AUTOSAR XML (schema 4-2-2)
package /STELLANTIS/EPT/ASWCs
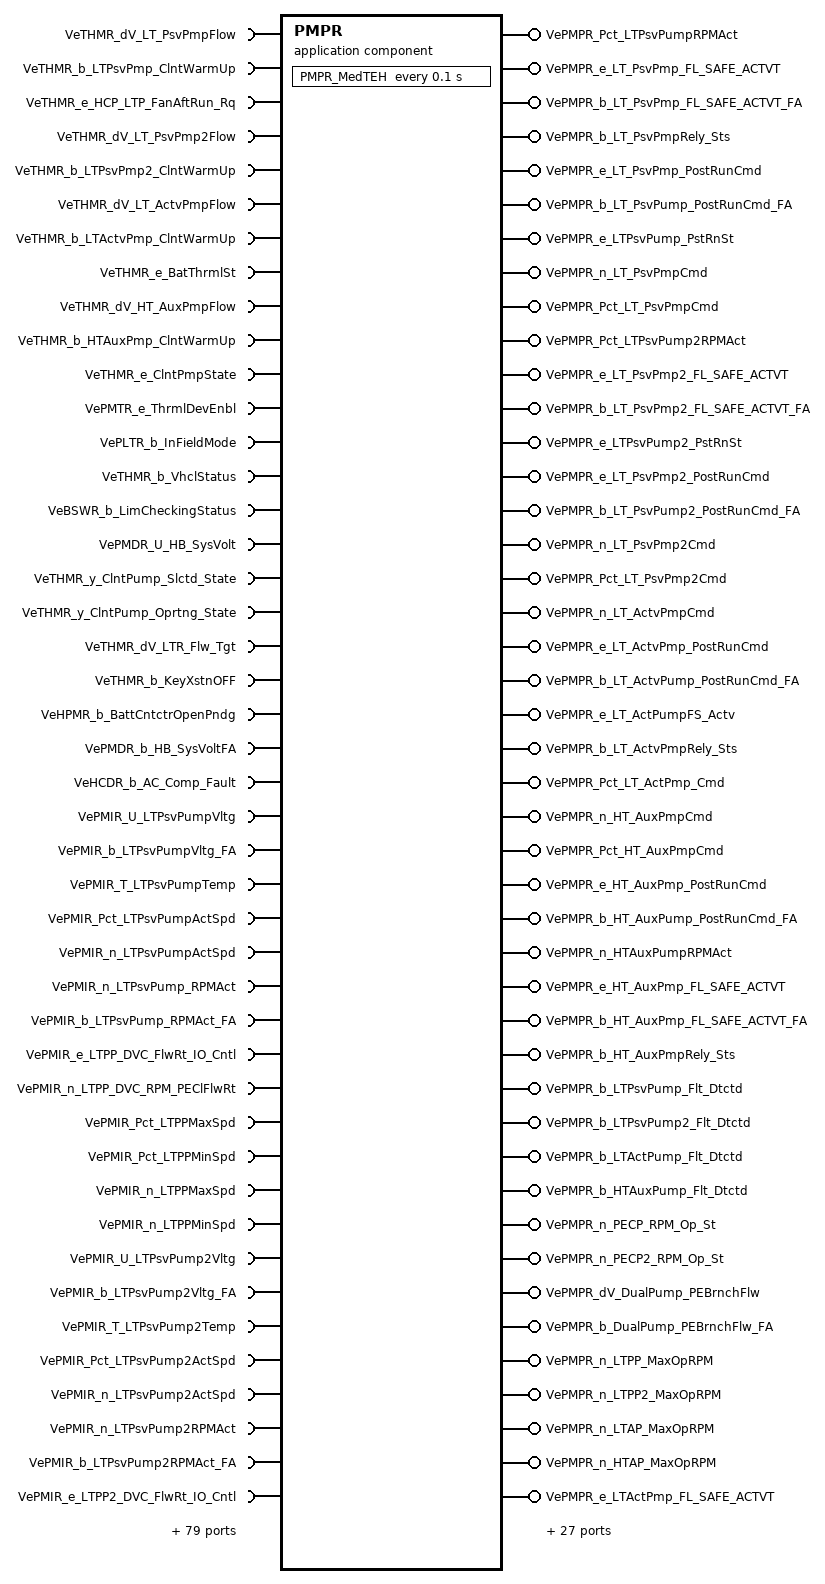
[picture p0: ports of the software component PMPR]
  application sw component type PMPR
    119 x require port:
      VeTHMR_dV_LT_PsvPmpFlow: variation-point={short-label=vpVeTHMR_dV_LT_PsvPmpFlow, sw-syscond=1}, nonqueued-receiver-com-spec{data-element=Value, init-value=0}, required-interface=VeTHMR_dV_LT_PsvPmpFlow
      VeTHMR_b_LTPsvPmp_ClntWarmUp: variation-point={short-label=vpVeTHMR_b_LTPsvPmp_ClntWarmUp, sw-syscond=1}, nonqueued-receiver-com-spec{data-element=Value, init-value=0}, required-interface=VeTHMR_b_LTPsvPmp_ClntWarmUp
      VeTHMR_e_HCP_LTP_FanAftRun_Rq: variation-point={short-label=vpVeTHMR_e_HCP_LTP_FanAftRun_Rq, sw-syscond=1}, nonqueued-receiver-com-spec{data-element=Value, init-value=CeTMIR_e_No_AftRunRequest}, required-interface=VeTHMR_e_HCP_LTP_FanAftRun_Rq
      VeTHMR_dV_LT_PsvPmp2Flow: variation-point={short-label=vpVeTHMR_dV_LT_PsvPmp2Flow, sw-syscond=1}, nonqueued-receiver-com-spec{data-element=Value, init-value=0}, required-interface=VeTHMR_dV_LT_PsvPmp2Flow
      VeTHMR_b_LTPsvPmp2_ClntWarmUp: variation-point={short-label=vpVeTHMR_b_LTPsvPmp2_ClntWarmUp, sw-syscond=1}, nonqueued-receiver-com-spec{data-element=Value, init-value=0}, required-interface=VeTHMR_b_LTPsvPmp2_ClntWarmUp
      VeTHMR_dV_LT_ActvPmpFlow: variation-point={short-label=vpVeTHMR_dV_LT_ActvPmpFlow, sw-syscond=1}, nonqueued-receiver-com-spec{data-element=Value, init-value=0}, required-interface=VeTHMR_dV_LT_ActvPmpFlow
      VeTHMR_b_LTActvPmp_ClntWarmUp: variation-point={short-label=vpVeTHMR_b_LTActvPmp_ClntWarmUp, sw-syscond=1}, nonqueued-receiver-com-spec{data-element=Value, init-value=0}, required-interface=VeTHMR_b_LTActvPmp_ClntWarmUp
      VeTHMR_e_BatThrmlSt: variation-point={short-label=vpVeTHMR_e_BatThrmlSt, sw-syscond=1}, nonqueued-receiver-com-spec{data-element=Value, init-value=CeTHMR_e_NoConditioning}, required-interface=VeTHMR_e_BatThrmlSt
      VeTHMR_dV_HT_AuxPmpFlow: variation-point={short-label=vpVeTHMR_dV_HT_AuxPmpFlow, sw-syscond=1}, nonqueued-receiver-com-spec{data-element=Value, init-value=0}, required-interface=VeTHMR_dV_HT_AuxPmpFlow
      VeTHMR_b_HTAuxPmp_ClntWarmUp: variation-point={short-label=vpVeTHMR_b_HTAuxPmp_ClntWarmUp, sw-syscond=1}, nonqueued-receiver-com-spec{data-element=Value, init-value=0}, required-interface=VeTHMR_b_HTAuxPmp_ClntWarmUp
      VeTHMR_e_ClntPmpState: variation-point={short-label=vpVeTHMR_e_ClntPmpState, sw-syscond=1}, nonqueued-receiver-com-spec{data-element=Value, init-value=CeTHMR_e_NoPump_On}, required-interface=VeTHMR_e_ClntPmpState
      VePMTR_e_ThrmlDevEnbl: variation-point={short-label=vpVePMTR_e_ThrmlDevEnbl, sw-syscond=1}, nonqueued-receiver-com-spec{data-element=Value, init-value=CePMTR_e_DISBL_All_Thrml}, required-interface=VePMTR_e_ThrmlDevEnbl
      VePLTR_b_InFieldMode: variation-point={short-label=vpVePLTR_b_InFieldMode, sw-syscond=1}, nonqueued-receiver-com-spec{data-element=Value, init-value=0}, required-interface=VePLTR_b_InFieldMode
      VeTHMR_b_VhclStatus: variation-point={short-label=vpVeTHMR_b_VhclStatus, sw-syscond=1}, nonqueued-receiver-com-spec{data-element=Value, init-value=0}, required-interface=VeTHMR_b_VhclStatus
      VeBSWR_b_LimCheckingStatus: variation-point={short-label=vpVeBSWR_b_LimCheckingStatus, sw-syscond=1}, nonqueued-receiver-com-spec{data-element=Value, init-value=0}, required-interface=VeBSWR_b_LimCheckingStatus
      VePMDR_U_HB_SysVolt: variation-point={short-label=vpVePMDR_U_HB_SysVolt, sw-syscond=1}, nonqueued-receiver-com-spec{data-element=Value, init-value=0}, required-interface=VePMDR_U_HB_SysVolt
      VeTHMR_y_ClntPump_Slctd_State: variation-point={short-label=vpVeTHMR_y_ClntPump_Slctd_State, sw-syscond=1}, nonqueued-receiver-com-spec{data-element=Value, init-value=0}, required-interface=VeTHMR_y_ClntPump_Slctd_State
      VeTHMR_y_ClntPump_Oprtng_State: variation-point={short-label=vpVeTHMR_y_ClntPump_Oprtng_State, sw-syscond=1}, nonqueued-receiver-com-spec{data-element=Value, init-value=0}, required-interface=VeTHMR_y_ClntPump_Oprtng_State
      VeTHMR_dV_LTR_Flw_Tgt: variation-point={short-label=vpVeTHMR_dV_LTR_Flw_Tgt, sw-syscond=1}, nonqueued-receiver-com-spec{data-element=Value, init-value=0}, required-interface=VeTHMR_dV_LTR_Flw_Tgt
      VeTHMR_b_KeyXstnOFF: variation-point={short-label=vpVeTHMR_b_KeyXstnOFF, sw-syscond=1}, nonqueued-receiver-com-spec{data-element=Value, init-value=0}, required-interface=VeTHMR_b_KeyXstnOFF
      VeHPMR_b_BattCntctrOpenPndg: variation-point={short-label=vpVeHPMR_b_BattCntctrOpenPndg, sw-syscond=1}, nonqueued-receiver-com-spec{data-element=Value, init-value=0}, required-interface=VeHPMR_b_BattCntctrOpenPndg
      VePMDR_b_HB_SysVoltFA: variation-point={short-label=vpVePMDR_b_HB_SysVoltFA, sw-syscond=1}, nonqueued-receiver-com-spec{data-element=Value, init-value=0}, required-interface=VePMDR_b_HB_SysVoltFA
      VeHCDR_b_AC_Comp_Fault: variation-point={short-label=vpVeHCDR_b_AC_Comp_Fault, sw-syscond=1}, nonqueued-receiver-com-spec{data-element=Value, init-value=0}, required-interface=VeHCDR_b_AC_Comp_Fault
      VePMIR_U_LTPsvPumpVltg: variation-point={short-label=vpVePMIR_U_LTPsvPumpVltg, sw-syscond=1}, nonqueued-receiver-com-spec{data-element=Value, init-value=0}, required-interface=VePMIR_U_LTPsvPumpVltg
      VePMIR_b_LTPsvPumpVltg_FA: variation-point={short-label=vpVePMIR_b_LTPsvPumpVltg_FA, sw-syscond=1}, nonqueued-receiver-com-spec{data-element=Value, init-value=0}, required-interface=VePMIR_b_LTPsvPumpVltg_FA
      VePMIR_T_LTPsvPumpTemp: variation-point={short-label=vpVePMIR_T_LTPsvPumpTemp, sw-syscond=1}, nonqueued-receiver-com-spec{data-element=Value, init-value=0}, required-interface=VePMIR_T_LTPsvPumpTemp
      VePMIR_Pct_LTPsvPumpActSpd: variation-point={short-label=vpVePMIR_Pct_LTPsvPumpActSpd, sw-syscond=1}, nonqueued-receiver-com-spec{data-element=Value, init-value=0}, required-interface=VePMIR_Pct_LTPsvPumpActSpd
      VePMIR_n_LTPsvPumpActSpd: variation-point={short-label=vpVePMIR_n_LTPsvPumpActSpd, sw-syscond=1}, nonqueued-receiver-com-spec{data-element=Value, init-value=0}, required-interface=VePMIR_n_LTPsvPumpActSpd
      VePMIR_n_LTPsvPump_RPMAct: variation-point={short-label=vpVePMIR_n_LTPsvPump_RPMAct, sw-syscond=1}, nonqueued-receiver-com-spec{data-element=Value, init-value=0}, required-interface=VePMIR_n_LTPsvPump_RPMAct
      VePMIR_b_LTPsvPump_RPMAct_FA: variation-point={short-label=vpVePMIR_b_LTPsvPump_RPMAct_FA, sw-syscond=1}, nonqueued-receiver-com-spec{data-element=Value, init-value=0}, required-interface=VePMIR_b_LTPsvPump_RPMAct_FA
      VePMIR_e_LTPP_DVC_FlwRt_IO_Cntl: variation-point={short-label=vpVePMIR_e_LTPP_DVC_FlwRt_IO_Cntl, sw-syscond=1}, nonqueued-receiver-com-spec{data-element=Value, init-value=CeTAIR_e_Return_Control_to_ECU}, required-interface=VePMIR_e_LTPP_DVC_FlwRt_IO_Cntl
      VePMIR_n_LTPP_DVC_RPM_PEClFlwRt: variation-point={short-label=vpVePMIR_n_LTPP_DVC_RPM_PEClFlwRt, sw-syscond=1}, nonqueued-receiver-com-spec{data-element=Value, init-value=0}, required-interface=VePMIR_n_LTPP_DVC_RPM_PEClFlwRt
      VePMIR_Pct_LTPPMaxSpd: variation-point={short-label=vpVePMIR_Pct_LTPPMaxSpd, sw-syscond=1}, nonqueued-receiver-com-spec{data-element=Value, init-value=0}, required-interface=VePMIR_Pct_LTPPMaxSpd
      VePMIR_Pct_LTPPMinSpd: variation-point={short-label=vpVePMIR_Pct_LTPPMinSpd, sw-syscond=1}, nonqueued-receiver-com-spec{data-element=Value, init-value=0}, required-interface=VePMIR_Pct_LTPPMinSpd
      VePMIR_n_LTPPMaxSpd: variation-point={short-label=vpVePMIR_n_LTPPMaxSpd, sw-syscond=1}, nonqueued-receiver-com-spec{data-element=Value, init-value=0}, required-interface=VePMIR_n_LTPPMaxSpd
      VePMIR_n_LTPPMinSpd: variation-point={short-label=vpVePMIR_n_LTPPMinSpd, sw-syscond=1}, nonqueued-receiver-com-spec{data-element=Value, init-value=0}, required-interface=VePMIR_n_LTPPMinSpd
      VePMIR_U_LTPsvPump2Vltg: variation-point={short-label=vpVePMIR_U_LTPsvPump2Vltg, sw-syscond=1}, nonqueued-receiver-com-spec{data-element=Value, init-value=0}, required-interface=VePMIR_U_LTPsvPump2Vltg
      VePMIR_b_LTPsvPump2Vltg_FA: variation-point={short-label=vpVePMIR_b_LTPsvPump2Vltg_FA, sw-syscond=1}, nonqueued-receiver-com-spec{data-element=Value, init-value=0}, required-interface=VePMIR_b_LTPsvPump2Vltg_FA
      VePMIR_T_LTPsvPump2Temp: variation-point={short-label=vpVePMIR_T_LTPsvPump2Temp, sw-syscond=1}, nonqueued-receiver-com-spec{data-element=Value, init-value=0}, required-interface=VePMIR_T_LTPsvPump2Temp
      VePMIR_Pct_LTPsvPump2ActSpd: variation-point={short-label=vpVePMIR_Pct_LTPsvPump2ActSpd, sw-syscond=1}, nonqueued-receiver-com-spec{data-element=Value, init-value=0}, required-interface=VePMIR_Pct_LTPsvPump2ActSpd
      VePMIR_n_LTPsvPump2ActSpd: variation-point={short-label=vpVePMIR_n_LTPsvPump2ActSpd, sw-syscond=1}, nonqueued-receiver-com-spec{data-element=Value, init-value=0}, required-interface=VePMIR_n_LTPsvPump2ActSpd
      VePMIR_n_LTPsvPump2RPMAct: variation-point={short-label=vpVePMIR_n_LTPsvPump2RPMAct, sw-syscond=1}, nonqueued-receiver-com-spec{data-element=Value, init-value=0}, required-interface=VePMIR_n_LTPsvPump2RPMAct
      VePMIR_b_LTPsvPump2RPMAct_FA: variation-point={short-label=vpVePMIR_b_LTPsvPump2RPMAct_FA, sw-syscond=1}, nonqueued-receiver-com-spec{data-element=Value, init-value=0}, required-interface=VePMIR_b_LTPsvPump2RPMAct_FA
      VePMIR_e_LTPP2_DVC_FlwRt_IO_Cntl: variation-point={short-label=vpVePMIR_e_LTPP2_DVC_FlwRt_IO_Cntl, sw-syscond=1}, nonqueued-receiver-com-spec{data-element=Value, init-value=CeTAIR_e_Return_Control_to_ECU}, required-interface=VePMIR_e_LTPP2_DVC_FlwRt_IO_Cntl
      VePMIR_n_LTPP2_DVC_RPM_PEClFlwRt: variation-point={short-label=vpVePMIR_n_LTPP2_DVC_RPM_PEClFlwRt, sw-syscond=1}, nonqueued-receiver-com-spec{data-element=Value, init-value=0}, required-interface=VePMIR_n_LTPP2_DVC_RPM_PEClFlwRt
      VePMIR_Pct_LTPP2MaxSpd: variation-point={short-label=vpVePMIR_Pct_LTPP2MaxSpd, sw-syscond=1}, nonqueued-receiver-com-spec{data-element=Value, init-value=0}, required-interface=VePMIR_Pct_LTPP2MaxSpd
      VePMIR_Pct_LTPP2MinSpd: variation-point={short-label=vpVePMIR_Pct_LTPP2MinSpd, sw-syscond=1}, nonqueued-receiver-com-spec{data-element=Value, init-value=0}, required-interface=VePMIR_Pct_LTPP2MinSpd
      VePMIR_n_LTPP2MaxSpd: variation-point={short-label=vpVePMIR_n_LTPP2MaxSpd, sw-syscond=1}, nonqueued-receiver-com-spec{data-element=Value, init-value=0}, required-interface=VePMIR_n_LTPP2MaxSpd
      VePMIR_n_LTPP2MinSpd: variation-point={short-label=vpVePMIR_n_LTPP2MinSpd, sw-syscond=1}, nonqueued-receiver-com-spec{data-element=Value, init-value=0}, required-interface=VePMIR_n_LTPP2MinSpd
      VePMIR_U_LTActvPumpVlt: variation-point={short-label=vpVePMIR_U_LTActvPumpVlt, sw-syscond=1}, nonqueued-receiver-com-spec{data-element=Value, init-value=0}, required-interface=VePMIR_U_LTActvPumpVlt
      VePMIR_b_LTActvPumpVlt_FA: variation-point={short-label=vpVePMIR_b_LTActvPumpVlt_FA, sw-syscond=1}, nonqueued-receiver-com-spec{data-element=Value, init-value=0}, required-interface=VePMIR_b_LTActvPumpVlt_FA
      VePMIR_T_LTActvPumpTemp: variation-point={short-label=vpVePMIR_T_LTActvPumpTemp, sw-syscond=1}, nonqueued-receiver-com-spec{data-element=Value, init-value=0}, required-interface=VePMIR_T_LTActvPumpTemp
      VePMIR_n_LTActvPumpRPMAct: variation-point={short-label=vpVePMIR_n_LTActvPumpRPMAct, sw-syscond=1}, nonqueued-receiver-com-spec{data-element=Value, init-value=0}, required-interface=VePMIR_n_LTActvPumpRPMAct
      VePMIR_b_LTActvPumpRPMAct_FA: variation-point={short-label=vpVePMIR_b_LTActvPumpRPMAct_FA, sw-syscond=1}, nonqueued-receiver-com-spec{data-element=Value, init-value=0}, required-interface=VePMIR_b_LTActvPumpRPMAct_FA
      VePMIR_e_LTAP_DVC_FlwRt_IO_Cntl: variation-point={short-label=vpVePMIR_e_LTAP_DVC_FlwRt_IO_Cntl, sw-syscond=1}, nonqueued-receiver-com-spec{data-element=Value, init-value=CeTAIR_e_Return_Control_to_ECU}, required-interface=VePMIR_e_LTAP_DVC_FlwRt_IO_Cntl
      VePMIR_n_LTAP_DVC_RPM_PEClFlwRt: variation-point={short-label=vpVePMIR_n_LTAP_DVC_RPM_PEClFlwRt, sw-syscond=1}, nonqueued-receiver-com-spec{data-element=Value, init-value=0}, required-interface=VePMIR_n_LTAP_DVC_RPM_PEClFlwRt
      VePMIR_U_HTAuxPumpVltg: variation-point={short-label=vpVePMIR_U_HTAuxPumpVltg, sw-syscond=1}, nonqueued-receiver-com-spec{data-element=Value, init-value=0}, required-interface=VePMIR_U_HTAuxPumpVltg
      VePMIR_b_HTAuxPumpVltg_FA: variation-point={short-label=vpVePMIR_b_HTAuxPumpVltg_FA, sw-syscond=1}, nonqueued-receiver-com-spec{data-element=Value, init-value=0}, required-interface=VePMIR_b_HTAuxPumpVltg_FA
      VePMIR_T_HTAuxPumpTemp: variation-point={short-label=vpVePMIR_T_HTAuxPumpTemp, sw-syscond=1}, nonqueued-receiver-com-spec{data-element=Value, init-value=0}, required-interface=VePMIR_T_HTAuxPumpTemp
      VePMIR_Pct_HTAuxPumpActSpd: variation-point={short-label=vpVePMIR_Pct_HTAuxPumpActSpd, sw-syscond=1}, nonqueued-receiver-com-spec{data-element=Value, init-value=0}, required-interface=VePMIR_Pct_HTAuxPumpActSpd
      VePMIR_n_HTAuxPumpRPMAct: variation-point={short-label=vpVePMIR_n_HTAuxPumpRPMAct, sw-syscond=1}, nonqueued-receiver-com-spec{data-element=Value, init-value=0}, required-interface=VePMIR_n_HTAuxPumpRPMAct
      VePMIR_e_HTAP_DVC_FlwRt_IO_Cntl: variation-point={short-label=vpVePMIR_e_HTAP_DVC_FlwRt_IO_Cntl, sw-syscond=1}, nonqueued-receiver-com-spec{data-element=Value, init-value=CeTAIR_e_Return_Control_to_ECU}, required-interface=VePMIR_e_HTAP_DVC_FlwRt_IO_Cntl
      VePMIR_n_HTAP_DVC_RPM_PEClFlwRt: variation-point={short-label=vpVePMIR_n_HTAP_DVC_RPM_PEClFlwRt, sw-syscond=1}, nonqueued-receiver-com-spec{data-element=Value, init-value=0}, required-interface=VePMIR_n_HTAP_DVC_RPM_PEClFlwRt
      VePMIR_Pct_HTAPMaxSpd: variation-point={short-label=vpVePMIR_Pct_HTAPMaxSpd, sw-syscond=1}, nonqueued-receiver-com-spec{data-element=Value, init-value=0}, required-interface=VePMIR_Pct_HTAPMaxSpd
      VePMIR_Pct_HTAPMinSpd: variation-point={short-label=vpVePMIR_Pct_HTAPMinSpd, sw-syscond=1}, nonqueued-receiver-com-spec{data-element=Value, init-value=0}, required-interface=VePMIR_Pct_HTAPMinSpd
      VePMIR_n_HTAPMaxSpd: variation-point={short-label=vpVePMIR_n_HTAPMaxSpd, sw-syscond=1}, nonqueued-receiver-com-spec{data-element=Value, init-value=0}, required-interface=VePMIR_n_HTAPMaxSpd
      VePMIR_n_HTAPMinSpd: variation-point={short-label=vpVePMIR_n_HTAPMinSpd, sw-syscond=1}, nonqueued-receiver-com-spec{data-element=Value, init-value=0}, required-interface=VePMIR_n_HTAPMinSpd
      VeTHMR_Pct_LINPrpVlv_Cmd: variation-point={short-label=vpVeTHMR_Pct_LINPrpVlv_Cmd, sw-syscond=1}, nonqueued-receiver-com-spec{data-element=Value, init-value=0}, required-interface=VeTHMR_Pct_LINPrpVlv_Cmd
      VeTHMR_n_HTLPumpMBCReq: variation-point={short-label=vpVeTHMR_n_HTLPumpMBCReq, sw-syscond=1}, nonqueued-receiver-com-spec{data-element=Value, init-value=0}, required-interface=VeTHMR_n_HTLPumpMBCReq
      VeTMIR_T_PsvPmpClnt_TmpIn: variation-point={short-label=vpVeTMIR_T_PsvPmpClnt_TmpIn, sw-syscond=1}, nonqueued-receiver-com-spec{data-element=Value, init-value=0}, required-interface=VeTMIR_T_PsvPmpClnt_TmpIn
      VeTRIR_T_HV_BatClntTmp_In: variation-point={short-label=vpVeTRIR_T_HV_BatClntTmp_In, sw-syscond=1}, nonqueued-receiver-com-spec{data-element=Value, init-value=0}, required-interface=VeTRIR_T_HV_BatClntTmp_In
      VeTRIR_T_HtrCorClnt_TmpIn: variation-point={short-label=vpVeTRIR_T_HtrCorClnt_TmpIn, sw-syscond=1}, nonqueued-receiver-com-spec{data-element=Value, init-value=0}, required-interface=VeTRIR_T_HtrCorClnt_TmpIn
      VeTMIR_T_OnBrdChrg_ClntTmpIn: variation-point={short-label=vpVeTMIR_T_OnBrdChrg_ClntTmpIn, sw-syscond=1}, nonqueued-receiver-com-spec{data-element=Value, init-value=0}, required-interface=VeTMIR_T_OnBrdChrg_ClntTmpIn
      VeTAIR_Pct_LTR_BypsVlv_ActlPstn: variation-point={short-label=vpVeTAIR_Pct_LTR_BypsVlv_ActlPstn, sw-syscond=1}, nonqueued-receiver-com-spec{data-element=Value, init-value=0}, required-interface=VeTAIR_Pct_LTR_BypsVlv_ActlPstn
      VeTAIR_Pct_HTL_BypsVlv_ActlPstn: variation-point={short-label=vpVeTAIR_Pct_HTL_BypsVlv_ActlPstn, sw-syscond=1}, nonqueued-receiver-com-spec{data-element=Value, init-value=0}, required-interface=VeTAIR_Pct_HTL_BypsVlv_ActlPstn
      VeTAIR_Pct_FrWyVlv_PstnAct: variation-point={short-label=vpVeTAIR_Pct_FrWyVlv_PstnAct, sw-syscond=1}, nonqueued-receiver-com-spec{data-element=Value, init-value=0}, required-interface=VeTAIR_Pct_FrWyVlv_PstnAct
      VeTHMR_y_PumpEnbl: variation-point={short-label=vpVeTHMR_y_PumpEnbl, sw-syscond=1}, nonqueued-receiver-com-spec{data-element=Value, init-value=0}, required-interface=VeTHMR_y_PumpEnbl
      VeTHMR_n_LTLPECP1MBC: variation-point={short-label=vpVeTHMR_n_LTLPECP1MBC, sw-syscond=1}, nonqueued-receiver-com-spec{data-element=Value, init-value=0}, required-interface=VeTHMR_n_LTLPECP1MBC
      VeTHMR_n_LTLPECP2MBC: variation-point={short-label=vpVeTHMR_n_LTLPECP2MBC, sw-syscond=1}, nonqueued-receiver-com-spec{data-element=Value, init-value=0}, required-interface=VeTHMR_n_LTLPECP2MBC
      VePMIR_b_HTAuxPumpRPMAct_FA: variation-point={short-label=vpVePMIR_b_HTAuxPumpRPMAct_FA, sw-syscond=1}, nonqueued-receiver-com-spec{data-element=Value, init-value=0}, required-interface=VePMIR_b_HTAuxPumpRPMAct_FA
      VeTAIR_b_FrWyVlv_PstnAct_FA: variation-point={short-label=vpVeTAIR_b_FrWyVlv_PstnAct_FA, sw-syscond=1}, nonqueued-receiver-com-spec{data-element=Value, init-value=0}, required-interface=VeTAIR_b_FrWyVlv_PstnAct_FA
      VeTAIR_b_LTR_BypsVlv_ActlPstn_FA: variation-point={short-label=vpVeTAIR_b_LTR_BypsVlv_ActlPstn_FA, sw-syscond=1}, nonqueued-receiver-com-spec{data-element=Value, init-value=0}, required-interface=VeTAIR_b_LTR_BypsVlv_ActlPstn_FA
      VeTAIR_b_HTL_BypsVlv_ActlPstn_FA: variation-point={short-label=vpVeTAIR_b_HTL_BypsVlv_ActlPstn_FA, sw-syscond=1}, nonqueued-receiver-com-spec{data-element=Value, init-value=0}, required-interface=VeTAIR_b_HTL_BypsVlv_ActlPstn_FA
      VeRCVR_e_CPV_Valve_Stuck_State: variation-point={short-label=vpVeRCVR_e_CPV_Valve_Stuck_State, sw-syscond=1}, nonqueued-receiver-com-spec{data-element=Value, init-value=CeRCVR_e_Closed}, required-interface=VeRCVR_e_CPV_Valve_Stuck_State
      VeRCVR_e_LTR_Valve_Stuck_State: variation-point={short-label=vpVeRCVR_e_LTR_Valve_Stuck_State, sw-syscond=1}, nonqueued-receiver-com-spec{data-element=Value, init-value=CeRCVR_e_Closed}, required-interface=VeRCVR_e_LTR_Valve_Stuck_State
      VeRCVR_e_HTL_Valve_Stuck_State: variation-point={short-label=vpVeRCVR_e_HTL_Valve_Stuck_State, sw-syscond=1}, nonqueued-receiver-com-spec{data-element=Value, init-value=CeRCVR_e_Closed}, required-interface=VeRCVR_e_HTL_Valve_Stuck_State
      VeBRDR_e_HV_Bat_CltLvlLo: variation-point={short-label=vpVeBRDR_e_HV_Bat_CltLvlLo, sw-syscond=1}, nonqueued-receiver-com-spec{data-element=Value, init-value=CeBRDR_e_BatCltLvlNotLo}, required-interface=VeBRDR_e_HV_Bat_CltLvlLo
      VeHTRR_P_HVC_HtrPwrAct: variation-point={short-label=vpVeHTRR_P_HVC_HtrPwrAct, sw-syscond=1}, nonqueued-receiver-com-spec{data-element=Value, init-value=0}, required-interface=VeHTRR_P_HVC_HtrPwrAct
      VeCITR_e_FOTA_Install_Type: variation-point={short-label=vpVeCITR_e_FOTA_Install_Type, sw-syscond=1}, nonqueued-receiver-com-spec{data-element=Value, init-value=CeCITR_e_NoFOTA}, required-interface=VeCITR_e_FOTA_Install_Type
      VeHTRR_P_HV_Htr4PwrAct: variation-point={short-label=vpVeHTRR_P_HV_Htr4PwrAct, sw-syscond=1}, nonqueued-receiver-com-spec{data-element=Value, init-value=0}, required-interface=VeHTRR_P_HV_Htr4PwrAct
      VeTHMR_n_BTLPumpMBCReq: variation-point={short-label=vpVeTHMR_n_BTLPumpMBCReq, sw-syscond=1}, nonqueued-receiver-com-spec{data-element=Value, init-value=0}, required-interface=VeTHMR_n_BTLPumpMBCReq
      VeDMAB_y_StatusByte_BattCoolLvlLow: nonqueued-receiver-com-spec{data-element=Value, init-value=0}, required-interface=VeDMAB_y_StatusByte_BattCoolLvlLow
      VeDMAB_y_StatusByte_LostCommMtrElectCoolPmpA: nonqueued-receiver-com-spec{data-element=Value, init-value=0}, required-interface=VeDMAB_y_StatusByte_LostCommMtrElectCoolPmpA
      VeDMAB_y_StatusByte_MtrElect_CoolPumAOvrSpd: nonqueued-receiver-com-spec{data-element=Value, init-value=0}, required-interface=VeDMAB_y_StatusByte_MtrElect_CoolPumAOvrSpd
      VeDMAB_y_StatusByte_PwrElecPmpPerf: nonqueued-receiver-com-spec{data-element=Value, init-value=0}, required-interface=VeDMAB_y_StatusByte_PwrElecPmpPerf
      VeDMAB_y_StatusByte_LostCommMtrElectCoolPmpB: nonqueued-receiver-com-spec{data-element=Value, init-value=0}, required-interface=VeDMAB_y_StatusByte_LostCommMtrElectCoolPmpB
      VeDMAB_y_StatusByte_LIN1_BusOff: nonqueued-receiver-com-spec{data-element=Value, init-value=0}, required-interface=VeDMAB_y_StatusByte_LIN1_BusOff
      VeDMAB_y_StatusByte_LIN2_BusOff: nonqueued-receiver-com-spec{data-element=Value, init-value=0}, required-interface=VeDMAB_y_StatusByte_LIN2_BusOff
      VeDMAB_y_StatusByte_MtrElect_CooPumBOvrSpd: nonqueued-receiver-com-spec{data-element=Value, init-value=0}, required-interface=VeDMAB_y_StatusByte_MtrElect_CooPumBOvrSpd
      VeDMAB_y_StatusByte_MtrElect_CoolPumBCtrlPerf: nonqueued-receiver-com-spec{data-element=Value, init-value=0}, required-interface=VeDMAB_y_StatusByte_MtrElect_CoolPumBCtrlPerf
      VeDMAB_y_StatusByte_BattCoolPmpOveSpd: nonqueued-receiver-com-spec{data-element=Value, init-value=0}, required-interface=VeDMAB_y_StatusByte_BattCoolPmpOveSpd
      VeDMAB_y_StatusByte_BattCoolPmpPerf: nonqueued-receiver-com-spec{data-element=Value, init-value=0}, required-interface=VeDMAB_y_StatusByte_BattCoolPmpPerf
      VePMIR_b_LTPsvPump2_PstRnStFA: variation-point={short-label=vpVePMIR_b_LTPsvPump2_PstRnStFA, sw-syscond=1}, nonqueued-receiver-com-spec{data-element=Value, init-value=0}, required-interface=VePMIR_b_LTPsvPump2_PstRnStFA
      VePMIR_e_LTPsvPump2_PstRnSt: variation-point={short-label=vpVePMIR_e_LTPsvPump2_PstRnSt, sw-syscond=1}, nonqueued-receiver-com-spec{data-element=Value, init-value=CeTMIR_e_No_AftRunRequest}, required-interface=VePMIR_e_LTPsvPump2_PstRnSt
      VePMIR_e_LTPsvPump_PstRnSt: variation-point={short-label=vpVePMIR_e_LTPsvPump_PstRnSt, sw-syscond=1}, nonqueued-receiver-com-spec{data-element=Value, init-value=CeTMIR_e_No_AftRunRequest}, required-interface=VePMIR_e_LTPsvPump_PstRnSt
      VePMIR_b_LTPsvPump_PstRnStFA: variation-point={short-label=vpVePMIR_b_LTPsvPump_PstRnStFA, sw-syscond=1}, nonqueued-receiver-com-spec{data-element=Value, init-value=0}, required-interface=VePMIR_b_LTPsvPump_PstRnStFA
      VeTRIR_T_HV_BatClntTmpOut: variation-point={short-label=vpVeTRIR_T_HV_BatClntTmpOut, sw-syscond=1}, nonqueued-receiver-com-spec{data-element=Value, init-value=0}, required-interface=VeTRIR_T_HV_BatClntTmpOut
      VeTMIR_T_ElecClntHtr_TmpIn: variation-point={short-label=vpVeTMIR_T_ElecClntHtr_TmpIn, sw-syscond=1}, nonqueued-receiver-com-spec{data-element=Value, init-value=0}, required-interface=VeTMIR_T_ElecClntHtr_TmpIn
      VeTRIR_T_HtrCorClnt_TmpOut: variation-point={short-label=vpVeTRIR_T_HtrCorClnt_TmpOut, sw-syscond=1}, nonqueued-receiver-com-spec{data-element=Value, init-value=0}, required-interface=VeTRIR_T_HtrCorClnt_TmpOut
      VeTMIR_T_LTR_ClntTmpOut: variation-point={short-label=vpVeTMIR_T_LTR_ClntTmpOut, sw-syscond=1}, nonqueued-receiver-com-spec{data-element=Value, init-value=0}, required-interface=VeTMIR_T_LTR_ClntTmpOut
      VeTHMR_dV_Branch_{1..3}_Flw: variation-point={short-label=vpVeTHMR_dV_Branch_{1..3}_Flw, sw-syscond=1}, nonqueued-receiver-com-spec{data-element=Value, init-value=0}, required-interface=VeTHMR_dV_Branch_{1..3}_Flw
      VeTMIR_b_PsvPmpClnt_TmpIn_FA: variation-point={short-label=vpVeTMIR_b_PsvPmpClnt_TmpIn_FA, sw-syscond=1}, nonqueued-receiver-com-spec{data-element=Value, init-value=0}, required-interface=VeTMIR_b_PsvPmpClnt_TmpIn_FA
      VeTMIR_b_OnBrdChrg_ClntTmpIn_FA: variation-point={short-label=vpVeTMIR_b_OnBrdChrg_ClntTmpIn_FA, sw-syscond=1}, nonqueued-receiver-com-spec{data-element=Value, init-value=0}, required-interface=VeTMIR_b_OnBrdChrg_ClntTmpIn_FA
      VeTHMR_Pct_FCCP_Req: variation-point={short-label=vpVeTHMR_Pct_FCCP_Req, sw-syscond=1}, nonqueued-receiver-com-spec{data-element=Value, init-value=0}, required-interface=VeTHMR_Pct_FCCP_Req
      VeBTRR_T_BTISBTIS2_Max: variation-point={short-label=vpVeBTRR_T_BTISBTIS2_Max, sw-syscond=1}, nonqueued-receiver-com-spec{data-element=Value, init-value=0}, required-interface=VeBTRR_T_BTISBTIS2_Max
      VeTHMR_T_AHPInletTempArb: variation-point={short-label=vpVeTHMR_T_AHPInletTempArb, sw-syscond=1}, nonqueued-receiver-com-spec{data-element=Value, init-value=0}, required-interface=VeTHMR_T_AHPInletTempArb
      VeRCVR_b_HT_Shtoff_VlvCmd: variation-point={short-label=vpVeRCVR_b_HT_Shtoff_VlvCmd, sw-syscond=1}, nonqueued-receiver-com-spec{data-element=Value, init-value=0}, required-interface=VeRCVR_b_HT_Shtoff_VlvCmd
    65 x provide port:
      VePMPR_Pct_LTPsvPumpRPMAct: variation-point={short-label=vpVePMPR_Pct_LTPsvPumpRPMAct, sw-syscond=1}, nonqueued-sender-com-spec{data-element=Value, init-value=0}, provided-interface=VePMPR_Pct_LTPsvPumpRPMAct
      VePMPR_e_LT_PsvPmp_FL_SAFE_ACTVT: variation-point={short-label=vpVePMPR_e_LT_PsvPmp_FL_SAFE_ACTVT, sw-syscond=1}, nonqueued-sender-com-spec{data-element=Value, init-value=CePMPR_e_FTSNA_False}, provided-interface=VePMPR_e_LT_PsvPmp_FL_SAFE_ACTVT
      VePMPR_b_LT_PsvPmp_FL_SAFE_ACTVT_FA: variation-point={short-label=vpVePMPR_b_LT_PsvPmp_FL_SAFE_ACTVT_FA, sw-syscond=1}, nonqueued-sender-com-spec{data-element=Value, init-value=0}, provided-interface=VePMPR_b_LT_PsvPmp_FL_SAFE_ACTVT_FA
      VePMPR_b_LT_PsvPmpRely_Sts: variation-point={short-label=vpVePMPR_b_LT_PsvPmpRely_Sts, sw-syscond=1}, nonqueued-sender-com-spec{data-element=Value, init-value=0}, provided-interface=VePMPR_b_LT_PsvPmpRely_Sts
      VePMPR_e_LT_PsvPmp_PostRunCmd: variation-point={short-label=vpVePMPR_e_LT_PsvPmp_PostRunCmd, sw-syscond=1}, nonqueued-sender-com-spec{data-element=Value, init-value=CeTMIR_e_No_AftRunRequest}, provided-interface=VePMPR_e_LT_PsvPmp_PostRunCmd
      VePMPR_b_LT_PsvPump_PostRunCmd_FA: variation-point={short-label=vpVePMPR_b_LT_PsvPump_PostRunCmd_FA, sw-syscond=1}, nonqueued-sender-com-spec{data-element=Value, init-value=0}, provided-interface=VePMPR_b_LT_PsvPump_PostRunCmd_FA
      VePMPR_e_LTPsvPump_PstRnSt: variation-point={short-label=vpVePMPR_e_LTPsvPump_PstRnSt, sw-syscond=1}, nonqueued-sender-com-spec{data-element=Value, init-value=CeTMIR_e_No_AftRunRequest}, provided-interface=VePMPR_e_LTPsvPump_PstRnSt
      VePMPR_n_LT_PsvPmpCmd: variation-point={short-label=vpVePMPR_n_LT_PsvPmpCmd, sw-syscond=1}, nonqueued-sender-com-spec{data-element=Value, init-value=0}, provided-interface=VePMPR_n_LT_PsvPmpCmd
      VePMPR_Pct_LT_PsvPmpCmd: variation-point={short-label=vpVePMPR_Pct_LT_PsvPmpCmd, sw-syscond=1}, nonqueued-sender-com-spec{data-element=Value, init-value=0}, provided-interface=VePMPR_Pct_LT_PsvPmpCmd
      VePMPR_Pct_LTPsvPump2RPMAct: variation-point={short-label=vpVePMPR_Pct_LTPsvPump2RPMAct, sw-syscond=1}, nonqueued-sender-com-spec{data-element=Value, init-value=0}, provided-interface=VePMPR_Pct_LTPsvPump2RPMAct
      VePMPR_e_LT_PsvPmp2_FL_SAFE_ACTVT: variation-point={short-label=vpVePMPR_e_LT_PsvPmp2_FL_SAFE_ACTVT, sw-syscond=1}, nonqueued-sender-com-spec{data-element=Value, init-value=CePMPR_e_FTSNA_False}, provided-interface=VePMPR_e_LT_PsvPmp2_FL_SAFE_ACTVT
      VePMPR_b_LT_PsvPmp2_FL_SAFE_ACTVT_FA: variation-point={short-label=vpVePMPR_b_LT_PsvPmp2_FL_SAFE_ACTVT_FA, sw-syscond=1}, nonqueued-sender-com-spec{data-element=Value, init-value=0}, provided-interface=VePMPR_b_LT_PsvPmp2_FL_SAFE_ACTVT_FA
      VePMPR_e_LTPsvPump2_PstRnSt: variation-point={short-label=vpVePMPR_e_LTPsvPump2_PstRnSt, sw-syscond=1}, nonqueued-sender-com-spec{data-element=Value, init-value=CeTMIR_e_No_AftRunRequest}, provided-interface=VePMPR_e_LTPsvPump2_PstRnSt
      VePMPR_e_LT_PsvPmp2_PostRunCmd: variation-point={short-label=vpVePMPR_e_LT_PsvPmp2_PostRunCmd, sw-syscond=1}, nonqueued-sender-com-spec{data-element=Value, init-value=CeTMIR_e_No_AftRunRequest}, provided-interface=VePMPR_e_LT_PsvPmp2_PostRunCmd
      VePMPR_b_LT_PsvPump2_PostRunCmd_FA: variation-point={short-label=vpVePMPR_b_LT_PsvPump2_PostRunCmd_FA, sw-syscond=1}, nonqueued-sender-com-spec{data-element=Value, init-value=0}, provided-interface=VePMPR_b_LT_PsvPump2_PostRunCmd_FA
      VePMPR_n_LT_PsvPmp2Cmd: variation-point={short-label=vpVePMPR_n_LT_PsvPmp2Cmd, sw-syscond=1}, nonqueued-sender-com-spec{data-element=Value, init-value=0}, provided-interface=VePMPR_n_LT_PsvPmp2Cmd
      VePMPR_Pct_LT_PsvPmp2Cmd: variation-point={short-label=vpVePMPR_Pct_LT_PsvPmp2Cmd, sw-syscond=1}, nonqueued-sender-com-spec{data-element=Value, init-value=0}, provided-interface=VePMPR_Pct_LT_PsvPmp2Cmd
      VePMPR_n_LT_ActvPmpCmd: variation-point={short-label=vpVePMPR_n_LT_ActvPmpCmd, sw-syscond=1}, nonqueued-sender-com-spec{data-element=Value, init-value=0}, provided-interface=VePMPR_n_LT_ActvPmpCmd
      VePMPR_e_LT_ActvPmp_PostRunCmd: variation-point={short-label=vpVePMPR_e_LT_ActvPmp_PostRunCmd, sw-syscond=1}, nonqueued-sender-com-spec{data-element=Value, init-value=CeTMIR_e_No_AftRunRequest}, provided-interface=VePMPR_e_LT_ActvPmp_PostRunCmd
      VePMPR_b_LT_ActvPump_PostRunCmd_FA: variation-point={short-label=vpVePMPR_b_LT_ActvPump_PostRunCmd_FA, sw-syscond=1}, nonqueued-sender-com-spec{data-element=Value, init-value=0}, provided-interface=VePMPR_b_LT_ActvPump_PostRunCmd_FA
      VePMPR_e_LT_ActPumpFS_Actv: variation-point={short-label=vpVePMPR_e_LT_ActPumpFS_Actv, sw-syscond=1}, nonqueued-sender-com-spec{data-element=Value, init-value=CePMPR_e_FTSNA_False}, provided-interface=VePMPR_e_LT_ActPumpFS_Actv
      VePMPR_b_LT_ActvPmpRely_Sts: variation-point={short-label=vpVePMPR_b_LT_ActvPmpRely_Sts, sw-syscond=1}, nonqueued-sender-com-spec{data-element=Value, init-value=0}, provided-interface=VePMPR_b_LT_ActvPmpRely_Sts
      VePMPR_Pct_LT_ActPmp_Cmd: variation-point={short-label=vpVePMPR_Pct_LT_ActPmp_Cmd, sw-syscond=1}, nonqueued-sender-com-spec{data-element=Value, init-value=0}, provided-interface=VePMPR_Pct_LT_ActPmp_Cmd
      VePMPR_n_HT_AuxPmpCmd: variation-point={short-label=vpVePMPR_n_HT_AuxPmpCmd, sw-syscond=1}, nonqueued-sender-com-spec{data-element=Value, init-value=0}, provided-interface=VePMPR_n_HT_AuxPmpCmd
      VePMPR_Pct_HT_AuxPmpCmd: variation-point={short-label=vpVePMPR_Pct_HT_AuxPmpCmd, sw-syscond=1}, nonqueued-sender-com-spec{data-element=Value, init-value=0}, provided-interface=VePMPR_Pct_HT_AuxPmpCmd
      VePMPR_e_HT_AuxPmp_PostRunCmd: variation-point={short-label=vpVePMPR_e_HT_AuxPmp_PostRunCmd, sw-syscond=1}, nonqueued-sender-com-spec{data-element=Value, init-value=CeTMIR_e_No_AftRunRequest}, provided-interface=VePMPR_e_HT_AuxPmp_PostRunCmd
      VePMPR_b_HT_AuxPump_PostRunCmd_FA: variation-point={short-label=vpVePMPR_b_HT_AuxPump_PostRunCmd_FA, sw-syscond=1}, nonqueued-sender-com-spec{data-element=Value, init-value=0}, provided-interface=VePMPR_b_HT_AuxPump_PostRunCmd_FA
      VePMPR_n_HTAuxPumpRPMAct: variation-point={short-label=vpVePMPR_n_HTAuxPumpRPMAct, sw-syscond=1}, nonqueued-sender-com-spec{data-element=Value, init-value=0}, provided-interface=VePMPR_n_HTAuxPumpRPMAct
      VePMPR_e_HT_AuxPmp_FL_SAFE_ACTVT: variation-point={short-label=vpVePMPR_e_HT_AuxPmp_FL_SAFE_ACTVT, sw-syscond=1}, nonqueued-sender-com-spec{data-element=Value, init-value=CePMPR_e_FTSNA_False}, provided-interface=VePMPR_e_HT_AuxPmp_FL_SAFE_ACTVT
      VePMPR_b_HT_AuxPmp_FL_SAFE_ACTVT_FA: variation-point={short-label=vpVePMPR_b_HT_AuxPmp_FL_SAFE_ACTVT_FA, sw-syscond=1}, nonqueued-sender-com-spec{data-element=Value, init-value=0}, provided-interface=VePMPR_b_HT_AuxPmp_FL_SAFE_ACTVT_FA
      VePMPR_b_HT_AuxPmpRely_Sts: variation-point={short-label=vpVePMPR_b_HT_AuxPmpRely_Sts, sw-syscond=1}, nonqueued-sender-com-spec{data-element=Value, init-value=0}, provided-interface=VePMPR_b_HT_AuxPmpRely_Sts
      VePMPR_b_LTPsvPump_Flt_Dtctd: variation-point={short-label=vpVePMPR_b_LTPsvPump_Flt_Dtctd, sw-syscond=1}, nonqueued-sender-com-spec{data-element=Value, init-value=0}, provided-interface=VePMPR_b_LTPsvPump_Flt_Dtctd
      VePMPR_b_LTPsvPump2_Flt_Dtctd: variation-point={short-label=vpVePMPR_b_LTPsvPump2_Flt_Dtctd, sw-syscond=1}, nonqueued-sender-com-spec{data-element=Value, init-value=0}, provided-interface=VePMPR_b_LTPsvPump2_Flt_Dtctd
      VePMPR_b_LTActPump_Flt_Dtctd: variation-point={short-label=vpVePMPR_b_LTActPump_Flt_Dtctd, sw-syscond=1}, nonqueued-sender-com-spec{data-element=Value, init-value=0}, provided-interface=VePMPR_b_LTActPump_Flt_Dtctd
      VePMPR_b_HTAuxPump_Flt_Dtctd: variation-point={short-label=vpVePMPR_b_HTAuxPump_Flt_Dtctd, sw-syscond=1}, nonqueued-sender-com-spec{data-element=Value, init-value=0}, provided-interface=VePMPR_b_HTAuxPump_Flt_Dtctd
      VePMPR_n_PECP_RPM_Op_St: variation-point={short-label=vpVePMPR_n_PECP_RPM_Op_St, sw-syscond=1}, nonqueued-sender-com-spec{data-element=Value, init-value=0}, provided-interface=VePMPR_n_PECP_RPM_Op_St
      VePMPR_n_PECP2_RPM_Op_St: variation-point={short-label=vpVePMPR_n_PECP2_RPM_Op_St, sw-syscond=1}, nonqueued-sender-com-spec{data-element=Value, init-value=0}, provided-interface=VePMPR_n_PECP2_RPM_Op_St
      VePMPR_dV_DualPump_PEBrnchFlw: nonqueued-sender-com-spec{data-element=Value, init-value=0}, provided-interface=VePMPR_dV_DualPump_PEBrnchFlw
      VePMPR_b_DualPump_PEBrnchFlw_FA: nonqueued-sender-com-spec{data-element=Value, init-value=0}, provided-interface=VePMPR_b_DualPump_PEBrnchFlw_FA
      VePMPR_n_LTPP_MaxOpRPM: variation-point={short-label=vpVePMPR_n_LTPP_MaxOpRPM, sw-syscond=1}, nonqueued-sender-com-spec{data-element=Value, init-value=0}, provided-interface=VePMPR_n_LTPP_MaxOpRPM
      VePMPR_n_LTPP2_MaxOpRPM: variation-point={short-label=vpVePMPR_n_LTPP2_MaxOpRPM, sw-syscond=1}, nonqueued-sender-com-spec{data-element=Value, init-value=0}, provided-interface=VePMPR_n_LTPP2_MaxOpRPM
      VePMPR_n_LTAP_MaxOpRPM: variation-point={short-label=vpVePMPR_n_LTAP_MaxOpRPM, sw-syscond=1}, nonqueued-sender-com-spec{data-element=Value, init-value=0}, provided-interface=VePMPR_n_LTAP_MaxOpRPM
      VePMPR_n_HTAP_MaxOpRPM: variation-point={short-label=vpVePMPR_n_HTAP_MaxOpRPM, sw-syscond=1}, nonqueued-sender-com-spec{data-element=Value, init-value=0}, provided-interface=VePMPR_n_HTAP_MaxOpRPM
      VePMPR_e_LTActPmp_FL_SAFE_ACTVT: variation-point={short-label=vpVePMPR_e_LTActPmp_FL_SAFE_ACTVT, sw-syscond=1}, nonqueued-sender-com-spec{data-element=Value, init-value=CePMPR_e_FTSNA_False}, provided-interface=VePMPR_e_LTActPmp_FL_SAFE_ACTVT
      VePMPR_b_LT_ActPmp_FL_SAFE_ACTVT_FA: variation-point={short-label=vpVePMPR_b_LT_ActPmp_FL_SAFE_ACTVT_FA, sw-syscond=1}, nonqueued-sender-com-spec{data-element=Value, init-value=0}, provided-interface=VePMPR_b_LT_ActPmp_FL_SAFE_ACTVT_FA
      VePMPR_dV_LTRFlw: nonqueued-sender-com-spec{data-element=Value, init-value=0}, provided-interface=VePMPR_dV_LTRFlw
      VePMPR_dV_BattFlw: variation-point={short-label=vpVePMPR_dV_BattFlw, sw-syscond=1}, nonqueued-sender-com-spec{data-element=Value, init-value=0}, provided-interface=VePMPR_dV_BattFlw
      VePMPR_dV_HtrFlw: variation-point={short-label=vpVePMPR_dV_HtrFlw, sw-syscond=1}, nonqueued-sender-com-spec{data-element=Value, init-value=0}, provided-interface=VePMPR_dV_HtrFlw
      VePMPR_dV_MtrFlw: nonqueued-sender-com-spec{data-element=Value, init-value=0}, provided-interface=VePMPR_dV_MtrFlw
      VePMPR_dV_PwrElecsFlw: nonqueued-sender-com-spec{data-element=Value, init-value=0}, provided-interface=VePMPR_dV_PwrElecsFlw
      VePMPR_b_RdyToShtDwn: variation-point={short-label=vpVePMPR_b_RdyToShtDwn, sw-syscond=1}, nonqueued-sender-com-spec{data-element=Value, init-value=0}, provided-interface=VePMPR_b_RdyToShtDwn
      VePMPR_n_FCCP_CtrlSpd: variation-point={short-label=vpVePMPR_n_FCCP_CtrlSpd, sw-syscond=1}, nonqueued-sender-com-spec{data-element=Value, init-value=0}, provided-interface=VePMPR_n_FCCP_CtrlSpd
      VePMPR_n_FCCP_SetCtrlSpd: variation-point={short-label=vpVePMPR_n_FCCP_SetCtrlSpd, sw-syscond=1}, nonqueued-sender-com-spec{data-element=Value, init-value=0}, provided-interface=VePMPR_n_FCCP_SetCtrlSpd
      VePMPR_e_FCCP_Default_VltgRngSlct: variation-point={short-label=vpVePMPR_e_FCCP_Default_VltgRngSlct, sw-syscond=1}, nonqueued-sender-com-spec{data-element=Value, init-value=CePMPR_e_FCCP_12Volts}, provided-interface=VePMPR_e_FCCP_Default_VltgRngSlct
      VePMPR_U_FCCP_Vltg_Enter_Default_Run: variation-point={short-label=vpVePMPR_U_FCCP_Vltg_Enter_Default_Run, sw-syscond=1}, nonqueued-sender-com-spec{data-element=Value, init-value=0}, provided-interface=VePMPR_U_FCCP_Vltg_Enter_Default_Run
      VePMPR_U_FCCP_VltgExitDefaultRun: variation-point={short-label=vpVePMPR_U_FCCP_VltgExitDefaultRun, sw-syscond=1}, nonqueued-sender-com-spec{data-element=Value, init-value=0}, provided-interface=VePMPR_U_FCCP_VltgExitDefaultRun
      VePMPR_t_FCCP_TimeExitDefaultRun: variation-point={short-label=vpVePMPR_t_FCCP_TimeExitDefaultRun, sw-syscond=1}, nonqueued-sender-com-spec{data-element=Value, init-value=0}, provided-interface=VePMPR_t_FCCP_TimeExitDefaultRun
      VePMPR_b_FCCP_Enbl: variation-point={short-label=vpVePMPR_b_FCCP_Enbl, sw-syscond=1}, nonqueued-sender-com-spec{data-element=Value, init-value=0}, provided-interface=VePMPR_b_FCCP_Enbl
      VePMPR_dV_GenFlw: nonqueued-sender-com-spec{data-element=Value, init-value=0}, provided-interface=VePMPR_dV_GenFlw
      VePMPR_dV_FuelCellFlw: variation-point={short-label=vpVePMPR_dV_FuelCellFlw, sw-syscond=1}, nonqueued-sender-com-spec{data-element=Value, init-value=0}, provided-interface=VePMPR_dV_FuelCellFlw
      VePMPR_dV_REDMFlw: nonqueued-sender-com-spec{data-element=Value, init-value=0}, provided-interface=VePMPR_dV_REDMFlw
      VePMPR_dV_FEDMFlw: nonqueued-sender-com-spec{data-element=Value, init-value=0}, provided-interface=VePMPR_dV_FEDMFlw
      VePMPR_b_FEDMFlw_FA: variation-point={short-label=vpVePMPR_b_FEDMFlw_FA, sw-syscond=1}, nonqueued-sender-com-spec{data-element=Value, init-value=0}, provided-interface=VePMPR_b_FEDMFlw_FA
      VePMPR_b_REDMFlw_FA: variation-point={short-label=vpVePMPR_b_REDMFlw_FA, sw-syscond=1}, nonqueued-sender-com-spec{data-element=Value, init-value=0}, provided-interface=VePMPR_b_REDMFlw_FA
      VePMPR_b_GenFlw_FA: variation-point={short-label=vpVePMPR_b_GenFlw_FA, sw-syscond=1}, nonqueued-sender-com-spec{data-element=Value, init-value=0}, provided-interface=VePMPR_b_GenFlw_FA
    6 x require port:
      NePMPR_n_LT_PsvPmpCmd_AD_Rx: nv-require-com-spec{init-value=0, variable=NePMPR_n_LT_PsvPmpCmd_AD}, required-interface=NePMPR_n_LT_PsvPmpCmd_AD
      NePMPR_e_LT_PsvPmp_PostRunCmd_AD_Rx: nv-require-com-spec{init-value=CeTMIR_e_No_AftRunRequest, variable=NePMPR_e_LT_PsvPmp_PostRunCmd_AD}, required-interface=NePMPR_e_LT_PsvPmp_PostRunCmd_AD
      NePMPR_n_LT_PsvPmp2Cmd_AD_Rx: nv-require-com-spec{init-value=0, variable=NePMPR_n_LT_PsvPmp2Cmd_AD}, required-interface=NePMPR_n_LT_PsvPmp2Cmd_AD
      NePMPR_e_LT_PsvPmp2_PostRunCmd_AD_Rx: nv-require-com-spec{init-value=CeTMIR_e_No_AftRunRequest, variable=NePMPR_e_LT_PsvPmp2_PostRunCmd_AD}, required-interface=NePMPR_e_LT_PsvPmp2_PostRunCmd_AD
      NePMPR_e_LTPsvPump_PstRnSt_Rx: nv-require-com-spec{init-value=CeTMIR_e_No_AftRunRequest, variable=NePMPR_e_LTPsvPump_PstRnSt}, required-interface=NePMPR_e_LTPsvPump_PstRnSt
      NePMPR_e_LTPsvPump2_PstRnSt_Rx: nv-require-com-spec{init-value=CeTMIR_e_No_AftRunRequest, variable=NePMPR_e_LTPsvPump2_PstRnSt}, required-interface=NePMPR_e_LTPsvPump2_PstRnSt
    6 x provide port:
      NePMPR_n_LT_PsvPmpCmd_AD: nv-provide-com-spec{ram-block-init-value=0, variable=NePMPR_n_LT_PsvPmpCmd_AD}, provided-interface=NePMPR_n_LT_PsvPmpCmd_AD
      NePMPR_e_LT_PsvPmp_PostRunCmd_AD: nv-provide-com-spec{ram-block-init-value=CeTMIR_e_No_AftRunRequest, variable=NePMPR_e_LT_PsvPmp_PostRunCmd_AD}, provided-interface=NePMPR_e_LT_PsvPmp_PostRunCmd_AD
      NePMPR_n_LT_PsvPmp2Cmd_AD: nv-provide-com-spec{ram-block-init-value=0, variable=NePMPR_n_LT_PsvPmp2Cmd_AD}, provided-interface=NePMPR_n_LT_PsvPmp2Cmd_AD
      NePMPR_e_LT_PsvPmp2_PostRunCmd_AD: nv-provide-com-spec{ram-block-init-value=CeTMIR_e_No_AftRunRequest, variable=NePMPR_e_LT_PsvPmp2_PostRunCmd_AD}, provided-interface=NePMPR_e_LT_PsvPmp2_PostRunCmd_AD
      NePMPR_e_LTPsvPump_PstRnSt: nv-provide-com-spec{ram-block-init-value=CeTMIR_e_No_AftRunRequest, variable=NePMPR_e_LTPsvPump_PstRnSt}, provided-interface=NePMPR_e_LTPsvPump_PstRnSt
      NePMPR_e_LTPsvPump2_PstRnSt: nv-provide-com-spec{ram-block-init-value=CeTMIR_e_No_AftRunRequest, variable=NePMPR_e_LTPsvPump2_PstRnSt}, provided-interface=NePMPR_e_LTPsvPump2_PstRnSt
    behavior IB_PMPR: data-type-mapping=msADTtoIDTMapping, handle-termination-and-restart=NO-SUPPORT
      timing event Event_MedTEH: start-on-event=PMPR_MedTEH, period=0.1
      init event Event_PMPR_ac_Init: start-on-event=PMPR_ac_Init
      init event Event_PwrOn: start-on-event=PMPR_PwrOn
      init event Event_PwrOff: start-on-event=PMPR_PwrOff
      4 x runnable:
        PMPR_ac_Init
          data-send-points:
            12 x access:
              OUT_VePMPR_e_LT_PsvPmp_FL_SAFE_ACTVT_Value: accessed-variable=VePMPR_e_LT_PsvPmp_FL_SAFE_ACTVT.Value, variation-point={short-label=vpOUT_VePMPR_e_LT_PsvPmp_FL_SAFE_ACTVT_Value, sw-syscond=1}
              OUT_VePMPR_e_LT_PsvPmp_PostRunCmd_Value: accessed-variable=VePMPR_e_LT_PsvPmp_PostRunCmd.Value, variation-point={short-label=vpOUT_VePMPR_e_LT_PsvPmp_PostRunCmd_Value, sw-syscond=1}
              OUT_VePMPR_e_LTPsvPump_PstRnSt_Value: accessed-variable=VePMPR_e_LTPsvPump_PstRnSt.Value, variation-point={short-label=vpOUT_VePMPR_e_LTPsvPump_PstRnSt_Value, sw-syscond=1}
              OUT_VePMPR_e_LT_PsvPmp2_FL_SAFE_ACTVT_Value: accessed-variable=VePMPR_e_LT_PsvPmp2_FL_SAFE_ACTVT.Value, variation-point={short-label=vpOUT_VePMPR_e_LT_PsvPmp2_FL_SAFE_ACTVT_Value, sw-syscond=1}
              OUT_VePMPR_e_LTPsvPump2_PstRnSt_Value: accessed-variable=VePMPR_e_LTPsvPump2_PstRnSt.Value, variation-point={short-label=vpOUT_VePMPR_e_LTPsvPump2_PstRnSt_Value, sw-syscond=1}
              OUT_VePMPR_e_LT_PsvPmp2_PostRunCmd_Value: accessed-variable=VePMPR_e_LT_PsvPmp2_PostRunCmd.Value, variation-point={short-label=vpOUT_VePMPR_e_LT_PsvPmp2_PostRunCmd_Value, sw-syscond=1}
              OUT_VePMPR_e_LT_ActvPmp_PostRunCmd_Value: accessed-variable=VePMPR_e_LT_ActvPmp_PostRunCmd.Value, variation-point={short-label=vpOUT_VePMPR_e_LT_ActvPmp_PostRunCmd_Value, sw-syscond=1}
              OUT_VePMPR_e_LT_ActPumpFS_Actv_Value: accessed-variable=VePMPR_e_LT_ActPumpFS_Actv.Value, variation-point={short-label=vpOUT_VePMPR_e_LT_ActPumpFS_Actv_Value, sw-syscond=1}
              OUT_VePMPR_e_HT_AuxPmp_PostRunCmd_Value: accessed-variable=VePMPR_e_HT_AuxPmp_PostRunCmd.Value, variation-point={short-label=vpOUT_VePMPR_e_HT_AuxPmp_PostRunCmd_Value, sw-syscond=1}
              OUT_VePMPR_e_HT_AuxPmp_FL_SAFE_ACTVT_Value: accessed-variable=VePMPR_e_HT_AuxPmp_FL_SAFE_ACTVT.Value, variation-point={short-label=vpOUT_VePMPR_e_HT_AuxPmp_FL_SAFE_ACTVT_Value, sw-syscond=1}
              OUT_VePMPR_e_LTActPmp_FL_SAFE_ACTVT_Value: accessed-variable=VePMPR_e_LTActPmp_FL_SAFE_ACTVT.Value, variation-point={short-label=vpOUT_VePMPR_e_LTActPmp_FL_SAFE_ACTVT_Value, sw-syscond=1}
              OUT_VePMPR_e_FCCP_Default_VltgRngSlct_Value: accessed-variable=VePMPR_e_FCCP_Default_VltgRngSlct.Value, variation-point={short-label=vpOUT_VePMPR_e_FCCP_Default_VltgRngSlct_Value, sw-syscond=1}
        PMPR_PwrOn
          data-receive-point-by-arguments:
            6 x access:
              IN_NePMPR_e_LTPsvPump2_PstRnSt_Rx_NePMPR_e_LTPsvPump2_PstRnSt: accessed-variable=NePMPR_e_LTPsvPump2_PstRnSt_Rx.NePMPR_e_LTPsvPump2_PstRnSt
              IN_NePMPR_e_LTPsvPump_PstRnSt_Rx_NePMPR_e_LTPsvPump_PstRnSt: accessed-variable=NePMPR_e_LTPsvPump_PstRnSt_Rx.NePMPR_e_LTPsvPump_PstRnSt
              IN_NePMPR_e_LT_PsvPmp2_PostRunCmd_AD_Rx_NePMPR_e_LT_PsvPmp2_PostRunCmd_AD: accessed-variable=NePMPR_e_LT_PsvPmp2_PostRunCmd_AD_Rx.NePMPR_e_LT_PsvPmp2_PostRunCmd_AD
              IN_NePMPR_e_LT_PsvPmp_PostRunCmd_AD_Rx_NePMPR_e_LT_PsvPmp_PostRunCmd_AD: accessed-variable=NePMPR_e_LT_PsvPmp_PostRunCmd_AD_Rx.NePMPR_e_LT_PsvPmp_PostRunCmd_AD
              IN_NePMPR_n_LT_PsvPmp2Cmd_AD_Rx_NePMPR_n_LT_PsvPmp2Cmd_AD: accessed-variable=NePMPR_n_LT_PsvPmp2Cmd_AD_Rx.NePMPR_n_LT_PsvPmp2Cmd_AD
              IN_NePMPR_n_LT_PsvPmpCmd_AD_Rx_NePMPR_n_LT_PsvPmpCmd_AD: accessed-variable=NePMPR_n_LT_PsvPmpCmd_AD_Rx.NePMPR_n_LT_PsvPmpCmd_AD
          data-send-points:
            65 x access:
              OUT_VePMPR_Pct_LTPsvPumpRPMAct_Value: accessed-variable=VePMPR_Pct_LTPsvPumpRPMAct.Value, variation-point={short-label=vpOUT_VePMPR_Pct_LTPsvPumpRPMAct_Value, sw-syscond=1}
              OUT_VePMPR_e_LT_PsvPmp_FL_SAFE_ACTVT_Value: accessed-variable=VePMPR_e_LT_PsvPmp_FL_SAFE_ACTVT.Value, variation-point={short-label=vpOUT_VePMPR_e_LT_PsvPmp_FL_SAFE_ACTVT_Value, sw-syscond=1}
              OUT_VePMPR_e_LT_PsvPmp2_FL_SAFE_ACTVT_Value: accessed-variable=VePMPR_e_LT_PsvPmp2_FL_SAFE_ACTVT.Value, variation-point={short-label=vpOUT_VePMPR_e_LT_PsvPmp2_FL_SAFE_ACTVT_Value, sw-syscond=1}
              OUT_VePMPR_b_LT_PsvPmp2_FL_SAFE_ACTVT_FA_Value: accessed-variable=VePMPR_b_LT_PsvPmp2_FL_SAFE_ACTVT_FA.Value, variation-point={short-label=vpOUT_VePMPR_b_LT_PsvPmp2_FL_SAFE_ACTVT_FA_Value, sw-syscond=1}
              OUT_VePMPR_e_LTPsvPump2_PstRnSt_Value: accessed-variable=VePMPR_e_LTPsvPump2_PstRnSt.Value, variation-point={short-label=vpOUT_VePMPR_e_LTPsvPump2_PstRnSt_Value, sw-syscond=1}
              OUT_VePMPR_e_LT_PsvPmp2_PostRunCmd_Value: accessed-variable=VePMPR_e_LT_PsvPmp2_PostRunCmd.Value, variation-point={short-label=vpOUT_VePMPR_e_LT_PsvPmp2_PostRunCmd_Value, sw-syscond=1}
              OUT_VePMPR_b_LT_PsvPump2_PostRunCmd_FA_Value: accessed-variable=VePMPR_b_LT_PsvPump2_PostRunCmd_FA.Value, variation-point={short-label=vpOUT_VePMPR_b_LT_PsvPump2_PostRunCmd_FA_Value, sw-syscond=1}
              OUT_VePMPR_n_LT_PsvPmp2Cmd_Value: accessed-variable=VePMPR_n_LT_PsvPmp2Cmd.Value, variation-point={short-label=vpOUT_VePMPR_n_LT_PsvPmp2Cmd_Value, sw-syscond=1}
              OUT_VePMPR_Pct_LT_PsvPmp2Cmd_Value: accessed-variable=VePMPR_Pct_LT_PsvPmp2Cmd.Value, variation-point={short-label=vpOUT_VePMPR_Pct_LT_PsvPmp2Cmd_Value, sw-syscond=1}
              OUT_VePMPR_b_LT_PsvPmp_FL_SAFE_ACTVT_FA_Value: accessed-variable=VePMPR_b_LT_PsvPmp_FL_SAFE_ACTVT_FA.Value, variation-point={short-label=vpOUT_VePMPR_b_LT_PsvPmp_FL_SAFE_ACTVT_FA_Value, sw-syscond=1}
              OUT_VePMPR_b_LTPsvPump_Flt_Dtctd_Value: accessed-variable=VePMPR_b_LTPsvPump_Flt_Dtctd.Value, variation-point={short-label=vpOUT_VePMPR_b_LTPsvPump_Flt_Dtctd_Value, sw-syscond=1}
              OUT_VePMPR_b_LT_PsvPmpRely_Sts_Value: accessed-variable=VePMPR_b_LT_PsvPmpRely_Sts.Value, variation-point={short-label=vpOUT_VePMPR_b_LT_PsvPmpRely_Sts_Value, sw-syscond=1}
              OUT_VePMPR_b_LTPsvPump2_Flt_Dtctd_Value: accessed-variable=VePMPR_b_LTPsvPump2_Flt_Dtctd.Value, variation-point={short-label=vpOUT_VePMPR_b_LTPsvPump2_Flt_Dtctd_Value, sw-syscond=1}
              OUT_VePMPR_dV_LTRFlw_Value: accessed-variable=VePMPR_dV_LTRFlw.Value
              OUT_VePMPR_e_LT_PsvPmp_PostRunCmd_Value: accessed-variable=VePMPR_e_LT_PsvPmp_PostRunCmd.Value, variation-point={short-label=vpOUT_VePMPR_e_LT_PsvPmp_PostRunCmd_Value, sw-syscond=1}
              OUT_VePMPR_dV_MtrFlw_Value: accessed-variable=VePMPR_dV_MtrFlw.Value
              OUT_VePMPR_dV_PwrElecsFlw_Value: accessed-variable=VePMPR_dV_PwrElecsFlw.Value
              OUT_VePMPR_b_LT_PsvPump_PostRunCmd_FA_Value: accessed-variable=VePMPR_b_LT_PsvPump_PostRunCmd_FA.Value, variation-point={short-label=vpOUT_VePMPR_b_LT_PsvPump_PostRunCmd_FA_Value, sw-syscond=1}
              OUT_VePMPR_n_PECP_RPM_Op_St_Value: accessed-variable=VePMPR_n_PECP_RPM_Op_St.Value, variation-point={short-label=vpOUT_VePMPR_n_PECP_RPM_Op_St_Value, sw-syscond=1}
              OUT_VePMPR_n_PECP2_RPM_Op_St_Value: accessed-variable=VePMPR_n_PECP2_RPM_Op_St.Value, variation-point={short-label=vpOUT_VePMPR_n_PECP2_RPM_Op_St_Value, sw-syscond=1}
              OUT_VePMPR_dV_DualPump_PEBrnchFlw_Value: accessed-variable=VePMPR_dV_DualPump_PEBrnchFlw.Value
              OUT_VePMPR_e_LTPsvPump_PstRnSt_Value: accessed-variable=VePMPR_e_LTPsvPump_PstRnSt.Value, variation-point={short-label=vpOUT_VePMPR_e_LTPsvPump_PstRnSt_Value, sw-syscond=1}
              OUT_VePMPR_b_DualPump_PEBrnchFlw_FA_Value: accessed-variable=VePMPR_b_DualPump_PEBrnchFlw_FA.Value
              OUT_VePMPR_n_LTPP_MaxOpRPM_Value: accessed-variable=VePMPR_n_LTPP_MaxOpRPM.Value, variation-point={short-label=vpOUT_VePMPR_n_LTPP_MaxOpRPM_Value, sw-syscond=1}
              OUT_VePMPR_n_LTPP2_MaxOpRPM_Value: accessed-variable=VePMPR_n_LTPP2_MaxOpRPM.Value, variation-point={short-label=vpOUT_VePMPR_n_LTPP2_MaxOpRPM_Value, sw-syscond=1}
              OUT_VePMPR_n_LT_PsvPmpCmd_Value: accessed-variable=VePMPR_n_LT_PsvPmpCmd.Value, variation-point={short-label=vpOUT_VePMPR_n_LT_PsvPmpCmd_Value, sw-syscond=1}
              OUT_VePMPR_Pct_LT_PsvPmpCmd_Value: accessed-variable=VePMPR_Pct_LT_PsvPmpCmd.Value, variation-point={short-label=vpOUT_VePMPR_Pct_LT_PsvPmpCmd_Value, sw-syscond=1}
              OUT_VePMPR_Pct_LTPsvPump2RPMAct_Value: accessed-variable=VePMPR_Pct_LTPsvPump2RPMAct.Value, variation-point={short-label=vpOUT_VePMPR_Pct_LTPsvPump2RPMAct_Value, sw-syscond=1}
              OUT_VePMPR_n_LT_ActvPmpCmd_Value: accessed-variable=VePMPR_n_LT_ActvPmpCmd.Value, variation-point={short-label=vpOUT_VePMPR_n_LT_ActvPmpCmd_Value, sw-syscond=1}
              OUT_VePMPR_e_LT_ActvPmp_PostRunCmd_Value: accessed-variable=VePMPR_e_LT_ActvPmp_PostRunCmd.Value, variation-point={short-label=vpOUT_VePMPR_e_LT_ActvPmp_PostRunCmd_Value, sw-syscond=1}
              OUT_VePMPR_b_LT_ActvPump_PostRunCmd_FA_Value: accessed-variable=VePMPR_b_LT_ActvPump_PostRunCmd_FA.Value, variation-point={short-label=vpOUT_VePMPR_b_LT_ActvPump_PostRunCmd_FA_Value, sw-syscond=1}
              OUT_VePMPR_e_LT_ActPumpFS_Actv_Value: accessed-variable=VePMPR_e_LT_ActPumpFS_Actv.Value, variation-point={short-label=vpOUT_VePMPR_e_LT_ActPumpFS_Actv_Value, sw-syscond=1}
              OUT_VePMPR_b_LT_ActvPmpRely_Sts_Value: accessed-variable=VePMPR_b_LT_ActvPmpRely_Sts.Value, variation-point={short-label=vpOUT_VePMPR_b_LT_ActvPmpRely_Sts_Value, sw-syscond=1}
              OUT_VePMPR_Pct_LT_ActPmp_Cmd_Value: accessed-variable=VePMPR_Pct_LT_ActPmp_Cmd.Value, variation-point={short-label=vpOUT_VePMPR_Pct_LT_ActPmp_Cmd_Value, sw-syscond=1}
              OUT_VePMPR_b_LTActPump_Flt_Dtctd_Value: accessed-variable=VePMPR_b_LTActPump_Flt_Dtctd.Value, variation-point={short-label=vpOUT_VePMPR_b_LTActPump_Flt_Dtctd_Value, sw-syscond=1}
              OUT_VePMPR_e_LTActPmp_FL_SAFE_ACTVT_Value: accessed-variable=VePMPR_e_LTActPmp_FL_SAFE_ACTVT.Value, variation-point={short-label=vpOUT_VePMPR_e_LTActPmp_FL_SAFE_ACTVT_Value, sw-syscond=1}
              OUT_VePMPR_b_LT_ActPmp_FL_SAFE_ACTVT_FA_Value: accessed-variable=VePMPR_b_LT_ActPmp_FL_SAFE_ACTVT_FA.Value, variation-point={short-label=vpOUT_VePMPR_b_LT_ActPmp_FL_SAFE_ACTVT_FA_Value, sw-syscond=1}
              OUT_VePMPR_dV_BattFlw_Value: accessed-variable=VePMPR_dV_BattFlw.Value, variation-point={short-label=vpOUT_VePMPR_dV_BattFlw_Value, sw-syscond=1}
              OUT_VePMPR_b_RdyToShtDwn_Value: accessed-variable=VePMPR_b_RdyToShtDwn.Value, variation-point={short-label=vpOUT_VePMPR_b_RdyToShtDwn_Value, sw-syscond=1}
              OUT_VePMPR_n_LTAP_MaxOpRPM_Value: accessed-variable=VePMPR_n_LTAP_MaxOpRPM.Value, variation-point={short-label=vpOUT_VePMPR_n_LTAP_MaxOpRPM_Value, sw-syscond=1}
              OUT_VePMPR_b_HT_AuxPump_PostRunCmd_FA_Value: accessed-variable=VePMPR_b_HT_AuxPump_PostRunCmd_FA.Value, variation-point={short-label=vpOUT_VePMPR_b_HT_AuxPump_PostRunCmd_FA_Value, sw-syscond=1}
              OUT_VePMPR_n_HTAuxPumpRPMAct_Value: accessed-variable=VePMPR_n_HTAuxPumpRPMAct.Value, variation-point={short-label=vpOUT_VePMPR_n_HTAuxPumpRPMAct_Value, sw-syscond=1}
              OUT_VePMPR_e_HT_AuxPmp_FL_SAFE_ACTVT_Value: accessed-variable=VePMPR_e_HT_AuxPmp_FL_SAFE_ACTVT.Value, variation-point={short-label=vpOUT_VePMPR_e_HT_AuxPmp_FL_SAFE_ACTVT_Value, sw-syscond=1}
              OUT_VePMPR_b_HT_AuxPmp_FL_SAFE_ACTVT_FA_Value: accessed-variable=VePMPR_b_HT_AuxPmp_FL_SAFE_ACTVT_FA.Value, variation-point={short-label=vpOUT_VePMPR_b_HT_AuxPmp_FL_SAFE_ACTVT_FA_Value, sw-syscond=1}
              OUT_VePMPR_b_HT_AuxPmpRely_Sts_Value: accessed-variable=VePMPR_b_HT_AuxPmpRely_Sts.Value, variation-point={short-label=vpOUT_VePMPR_b_HT_AuxPmpRely_Sts_Value, sw-syscond=1}
              OUT_VePMPR_n_HT_AuxPmpCmd_Value: accessed-variable=VePMPR_n_HT_AuxPmpCmd.Value, variation-point={short-label=vpOUT_VePMPR_n_HT_AuxPmpCmd_Value, sw-syscond=1}
              OUT_VePMPR_Pct_HT_AuxPmpCmd_Value: accessed-variable=VePMPR_Pct_HT_AuxPmpCmd.Value, variation-point={short-label=vpOUT_VePMPR_Pct_HT_AuxPmpCmd_Value, sw-syscond=1}
              OUT_VePMPR_e_HT_AuxPmp_PostRunCmd_Value: accessed-variable=VePMPR_e_HT_AuxPmp_PostRunCmd.Value, variation-point={short-label=vpOUT_VePMPR_e_HT_AuxPmp_PostRunCmd_Value, sw-syscond=1}
              OUT_VePMPR_n_HTAP_MaxOpRPM_Value: accessed-variable=VePMPR_n_HTAP_MaxOpRPM.Value, variation-point={short-label=vpOUT_VePMPR_n_HTAP_MaxOpRPM_Value, sw-syscond=1}
              OUT_VePMPR_dV_HtrFlw_Value: accessed-variable=VePMPR_dV_HtrFlw.Value, variation-point={short-label=vpOUT_VePMPR_dV_HtrFlw_Value, sw-syscond=1}
              OUT_VePMPR_n_FCCP_CtrlSpd_Value: accessed-variable=VePMPR_n_FCCP_CtrlSpd.Value, variation-point={short-label=vpOUT_VePMPR_n_FCCP_CtrlSpd_Value, sw-syscond=1}
              OUT_VePMPR_b_HTAuxPump_Flt_Dtctd_Value: accessed-variable=VePMPR_b_HTAuxPump_Flt_Dtctd.Value, variation-point={short-label=vpOUT_VePMPR_b_HTAuxPump_Flt_Dtctd_Value, sw-syscond=1}
              OUT_VePMPR_n_FCCP_SetCtrlSpd_Value: accessed-variable=VePMPR_n_FCCP_SetCtrlSpd.Value, variation-point={short-label=vpOUT_VePMPR_n_FCCP_SetCtrlSpd_Value, sw-syscond=1}
              OUT_VePMPR_e_FCCP_Default_VltgRngSlct_Value: accessed-variable=VePMPR_e_FCCP_Default_VltgRngSlct.Value, variation-point={short-label=vpOUT_VePMPR_e_FCCP_Default_VltgRngSlct_Value, sw-syscond=1}
              OUT_VePMPR_U_FCCP_Vltg_Enter_Default_Run_Value: accessed-variable=VePMPR_U_FCCP_Vltg_Enter_Default_Run.Value, variation-point={short-label=vpOUT_VePMPR_U_FCCP_Vltg_Enter_Default_Run_Value, sw-syscond=1}
              OUT_VePMPR_U_FCCP_VltgExitDefaultRun_Value: accessed-variable=VePMPR_U_FCCP_VltgExitDefaultRun.Value, variation-point={short-label=vpOUT_VePMPR_U_FCCP_VltgExitDefaultRun_Value, sw-syscond=1}
              OUT_VePMPR_t_FCCP_TimeExitDefaultRun_Value: accessed-variable=VePMPR_t_FCCP_TimeExitDefaultRun.Value, variation-point={short-label=vpOUT_VePMPR_t_FCCP_TimeExitDefaultRun_Value, sw-syscond=1}
              OUT_VePMPR_b_FCCP_Enbl_Value: accessed-variable=VePMPR_b_FCCP_Enbl.Value, variation-point={short-label=vpOUT_VePMPR_b_FCCP_Enbl_Value, sw-syscond=1}
              OUT_VePMPR_dV_GenFlw_Value: accessed-variable=VePMPR_dV_GenFlw.Value
              OUT_VePMPR_dV_FuelCellFlw_Value: accessed-variable=VePMPR_dV_FuelCellFlw.Value, variation-point={short-label=vpOUT_VePMPR_dV_FuelCellFlw_Value, sw-syscond=1}
              OUT_VePMPR_dV_FEDMFlw_Value: accessed-variable=VePMPR_dV_FEDMFlw.Value
              OUT_VePMPR_dV_REDMFlw_Value: accessed-variable=VePMPR_dV_REDMFlw.Value
              OUT_VePMPR_b_FEDMFlw_FA_Value: accessed-variable=VePMPR_b_FEDMFlw_FA.Value, variation-point={short-label=vpOUT_VePMPR_b_FEDMFlw_FA_Value, sw-syscond=1}
              OUT_VePMPR_b_REDMFlw_FA_Value: accessed-variable=VePMPR_b_REDMFlw_FA.Value, variation-point={short-label=vpOUT_VePMPR_b_REDMFlw_FA_Value, sw-syscond=1}
              OUT_VePMPR_b_GenFlw_FA_Value: accessed-variable=VePMPR_b_GenFlw_FA.Value, variation-point={short-label=vpOUT_VePMPR_b_GenFlw_FA_Value, sw-syscond=1}
        PMPR_MedTEH
          data-receive-point-by-arguments:
            115 x access:
              IN_VeBRDR_e_HV_Bat_CltLvlLo_Value: accessed-variable=VeBRDR_e_HV_Bat_CltLvlLo.Value, variation-point={short-label=vpIN_VeBRDR_e_HV_Bat_CltLvlLo_Value, sw-syscond=1}
              IN_VeBSWR_b_LimCheckingStatus_Value: accessed-variable=VeBSWR_b_LimCheckingStatus.Value, variation-point={short-label=vpIN_VeBSWR_b_LimCheckingStatus_Value, sw-syscond=1}
              IN_VeBTRR_T_BTISBTIS2_Max_Value: accessed-variable=VeBTRR_T_BTISBTIS2_Max.Value, variation-point={short-label=vpIN_VeBTRR_T_BTISBTIS2_Max_Value, sw-syscond=1}
              IN_VeCITR_e_FOTA_Install_Type_Value: accessed-variable=VeCITR_e_FOTA_Install_Type.Value, variation-point={short-label=vpIN_VeCITR_e_FOTA_Install_Type_Value, sw-syscond=1}
              IN_VeDMAB_y_StatusByte_BattCoolLvlLow_Value: accessed-variable=VeDMAB_y_StatusByte_BattCoolLvlLow.Value
              IN_VeDMAB_y_StatusByte_BattCoolPmpOveSpd_Value: accessed-variable=VeDMAB_y_StatusByte_BattCoolPmpOveSpd.Value
              IN_VeDMAB_y_StatusByte_BattCoolPmpPerf_Value: accessed-variable=VeDMAB_y_StatusByte_BattCoolPmpPerf.Value
              IN_VeDMAB_y_StatusByte_LIN1_BusOff_Value: accessed-variable=VeDMAB_y_StatusByte_LIN1_BusOff.Value
              IN_VeDMAB_y_StatusByte_LIN2_BusOff_Value: accessed-variable=VeDMAB_y_StatusByte_LIN2_BusOff.Value
              IN_VeDMAB_y_StatusByte_LostCommMtrElectCoolPmpA_Value: accessed-variable=VeDMAB_y_StatusByte_LostCommMtrElectCoolPmpA.Value
              IN_VeDMAB_y_StatusByte_LostCommMtrElectCoolPmpB_Value: accessed-variable=VeDMAB_y_StatusByte_LostCommMtrElectCoolPmpB.Value
              IN_VeDMAB_y_StatusByte_MtrElect_CooPumBOvrSpd_Value: accessed-variable=VeDMAB_y_StatusByte_MtrElect_CooPumBOvrSpd.Value
              IN_VeDMAB_y_StatusByte_MtrElect_CoolPumAOvrSpd_Value: accessed-variable=VeDMAB_y_StatusByte_MtrElect_CoolPumAOvrSpd.Value
              IN_VeDMAB_y_StatusByte_MtrElect_CoolPumBCtrlPerf_Value: accessed-variable=VeDMAB_y_StatusByte_MtrElect_CoolPumBCtrlPerf.Value
              IN_VeDMAB_y_StatusByte_PwrElecPmpPerf_Value: accessed-variable=VeDMAB_y_StatusByte_PwrElecPmpPerf.Value
              IN_VeHCDR_b_AC_Comp_Fault_Value: accessed-variable=VeHCDR_b_AC_Comp_Fault.Value, variation-point={short-label=vpIN_VeHCDR_b_AC_Comp_Fault_Value, sw-syscond=1}
              IN_VeHPMR_b_BattCntctrOpenPndg_Value: accessed-variable=VeHPMR_b_BattCntctrOpenPndg.Value, variation-point={short-label=vpIN_VeHPMR_b_BattCntctrOpenPndg_Value, sw-syscond=1}
              IN_VeHTRR_P_HVC_HtrPwrAct_Value: accessed-variable=VeHTRR_P_HVC_HtrPwrAct.Value, variation-point={short-label=vpIN_VeHTRR_P_HVC_HtrPwrAct_Value, sw-syscond=1}
              IN_VeHTRR_P_HV_Htr4PwrAct_Value: accessed-variable=VeHTRR_P_HV_Htr4PwrAct.Value, variation-point={short-label=vpIN_VeHTRR_P_HV_Htr4PwrAct_Value, sw-syscond=1}
              IN_VePLTR_b_InFieldMode_Value: accessed-variable=VePLTR_b_InFieldMode.Value, variation-point={short-label=vpIN_VePLTR_b_InFieldMode_Value, sw-syscond=1}
              IN_VePMDR_U_HB_SysVolt_Value: accessed-variable=VePMDR_U_HB_SysVolt.Value, variation-point={short-label=vpIN_VePMDR_U_HB_SysVolt_Value, sw-syscond=1}
              IN_VePMDR_b_HB_SysVoltFA_Value: accessed-variable=VePMDR_b_HB_SysVoltFA.Value, variation-point={short-label=vpIN_VePMDR_b_HB_SysVoltFA_Value, sw-syscond=1}
              IN_VePMIR_Pct_HTAPMaxSpd_Value: accessed-variable=VePMIR_Pct_HTAPMaxSpd.Value, variation-point={short-label=vpIN_VePMIR_Pct_HTAPMaxSpd_Value, sw-syscond=1}
              IN_VePMIR_Pct_HTAPMinSpd_Value: accessed-variable=VePMIR_Pct_HTAPMinSpd.Value, variation-point={short-label=vpIN_VePMIR_Pct_HTAPMinSpd_Value, sw-syscond=1}
              IN_VePMIR_Pct_LTPP2MaxSpd_Value: accessed-variable=VePMIR_Pct_LTPP2MaxSpd.Value, variation-point={short-label=vpIN_VePMIR_Pct_LTPP2MaxSpd_Value, sw-syscond=1}
              IN_VePMIR_Pct_LTPP2MinSpd_Value: accessed-variable=VePMIR_Pct_LTPP2MinSpd.Value, variation-point={short-label=vpIN_VePMIR_Pct_LTPP2MinSpd_Value, sw-syscond=1}
              IN_VePMIR_Pct_LTPPMaxSpd_Value: accessed-variable=VePMIR_Pct_LTPPMaxSpd.Value, variation-point={short-label=vpIN_VePMIR_Pct_LTPPMaxSpd_Value, sw-syscond=1}
              IN_VePMIR_Pct_LTPPMinSpd_Value: accessed-variable=VePMIR_Pct_LTPPMinSpd.Value, variation-point={short-label=vpIN_VePMIR_Pct_LTPPMinSpd_Value, sw-syscond=1}
              IN_VePMIR_Pct_LTPsvPump2ActSpd_Value: accessed-variable=VePMIR_Pct_LTPsvPump2ActSpd.Value, variation-point={short-label=vpIN_VePMIR_Pct_LTPsvPump2ActSpd_Value, sw-syscond=1}
              IN_VePMIR_Pct_LTPsvPumpActSpd_Value: accessed-variable=VePMIR_Pct_LTPsvPumpActSpd.Value, variation-point={short-label=vpIN_VePMIR_Pct_LTPsvPumpActSpd_Value, sw-syscond=1}
              IN_VePMIR_T_HTAuxPumpTemp_Value: accessed-variable=VePMIR_T_HTAuxPumpTemp.Value, variation-point={short-label=vpIN_VePMIR_T_HTAuxPumpTemp_Value, sw-syscond=1}
              IN_VePMIR_T_LTActvPumpTemp_Value: accessed-variable=VePMIR_T_LTActvPumpTemp.Value, variation-point={short-label=vpIN_VePMIR_T_LTActvPumpTemp_Value, sw-syscond=1}
              IN_VePMIR_T_LTPsvPump2Temp_Value: accessed-variable=VePMIR_T_LTPsvPump2Temp.Value, variation-point={short-label=vpIN_VePMIR_T_LTPsvPump2Temp_Value, sw-syscond=1}
              IN_VePMIR_T_LTPsvPumpTemp_Value: accessed-variable=VePMIR_T_LTPsvPumpTemp.Value, variation-point={short-label=vpIN_VePMIR_T_LTPsvPumpTemp_Value, sw-syscond=1}
              IN_VePMIR_U_HTAuxPumpVltg_Value: accessed-variable=VePMIR_U_HTAuxPumpVltg.Value, variation-point={short-label=vpIN_VePMIR_U_HTAuxPumpVltg_Value, sw-syscond=1}
              IN_VePMIR_U_LTActvPumpVlt_Value: accessed-variable=VePMIR_U_LTActvPumpVlt.Value, variation-point={short-label=vpIN_VePMIR_U_LTActvPumpVlt_Value, sw-syscond=1}
              IN_VePMIR_U_LTPsvPump2Vltg_Value: accessed-variable=VePMIR_U_LTPsvPump2Vltg.Value, variation-point={short-label=vpIN_VePMIR_U_LTPsvPump2Vltg_Value, sw-syscond=1}
              IN_VePMIR_U_LTPsvPumpVltg_Value: accessed-variable=VePMIR_U_LTPsvPumpVltg.Value, variation-point={short-label=vpIN_VePMIR_U_LTPsvPumpVltg_Value, sw-syscond=1}
              IN_VePMIR_b_HTAuxPumpRPMAct_FA_Value: accessed-variable=VePMIR_b_HTAuxPumpRPMAct_FA.Value, variation-point={short-label=vpIN_VePMIR_b_HTAuxPumpRPMAct_FA_Value, sw-syscond=1}
              IN_VePMIR_b_HTAuxPumpVltg_FA_Value: accessed-variable=VePMIR_b_HTAuxPumpVltg_FA.Value, variation-point={short-label=vpIN_VePMIR_b_HTAuxPumpVltg_FA_Value, sw-syscond=1}
              IN_VePMIR_b_LTActvPumpRPMAct_FA_Value: accessed-variable=VePMIR_b_LTActvPumpRPMAct_FA.Value, variation-point={short-label=vpIN_VePMIR_b_LTActvPumpRPMAct_FA_Value, sw-syscond=1}
              IN_VePMIR_b_LTActvPumpVlt_FA_Value: accessed-variable=VePMIR_b_LTActvPumpVlt_FA.Value, variation-point={short-label=vpIN_VePMIR_b_LTActvPumpVlt_FA_Value, sw-syscond=1}
              IN_VePMIR_b_LTPsvPump2RPMAct_FA_Value: accessed-variable=VePMIR_b_LTPsvPump2RPMAct_FA.Value, variation-point={short-label=vpIN_VePMIR_b_LTPsvPump2RPMAct_FA_Value, sw-syscond=1}
              IN_VePMIR_b_LTPsvPump2Vltg_FA_Value: accessed-variable=VePMIR_b_LTPsvPump2Vltg_FA.Value, variation-point={short-label=vpIN_VePMIR_b_LTPsvPump2Vltg_FA_Value, sw-syscond=1}
              IN_VePMIR_b_LTPsvPumpVltg_FA_Value: accessed-variable=VePMIR_b_LTPsvPumpVltg_FA.Value, variation-point={short-label=vpIN_VePMIR_b_LTPsvPumpVltg_FA_Value, sw-syscond=1}
              IN_VePMIR_b_LTPsvPump_RPMAct_FA_Value: accessed-variable=VePMIR_b_LTPsvPump_RPMAct_FA.Value, variation-point={short-label=vpIN_VePMIR_b_LTPsvPump_RPMAct_FA_Value, sw-syscond=1}
              IN_VePMIR_e_HTAP_DVC_FlwRt_IO_Cntl_Value: accessed-variable=VePMIR_e_HTAP_DVC_FlwRt_IO_Cntl.Value, variation-point={short-label=vpIN_VePMIR_e_HTAP_DVC_FlwRt_IO_Cntl_Value, sw-syscond=1}
              IN_VePMIR_e_LTAP_DVC_FlwRt_IO_Cntl_Value: accessed-variable=VePMIR_e_LTAP_DVC_FlwRt_IO_Cntl.Value, variation-point={short-label=vpIN_VePMIR_e_LTAP_DVC_FlwRt_IO_Cntl_Value, sw-syscond=1}
              IN_VePMIR_e_LTPP2_DVC_FlwRt_IO_Cntl_Value: accessed-variable=VePMIR_e_LTPP2_DVC_FlwRt_IO_Cntl.Value, variation-point={short-label=vpIN_VePMIR_e_LTPP2_DVC_FlwRt_IO_Cntl_Value, sw-syscond=1}
              IN_VePMIR_e_LTPP_DVC_FlwRt_IO_Cntl_Value: accessed-variable=VePMIR_e_LTPP_DVC_FlwRt_IO_Cntl.Value, variation-point={short-label=vpIN_VePMIR_e_LTPP_DVC_FlwRt_IO_Cntl_Value, sw-syscond=1}
              IN_VePMIR_e_LTPsvPump2_PstRnSt_Value: accessed-variable=VePMIR_e_LTPsvPump2_PstRnSt.Value, variation-point={short-label=vpIN_VePMIR_e_LTPsvPump2_PstRnSt_Value, sw-syscond=1}
              IN_VePMIR_e_LTPsvPump_PstRnSt_Value: accessed-variable=VePMIR_e_LTPsvPump_PstRnSt.Value, variation-point={short-label=vpIN_VePMIR_e_LTPsvPump_PstRnSt_Value, sw-syscond=1}
              IN_VePMIR_n_HTAPMaxSpd_Value: accessed-variable=VePMIR_n_HTAPMaxSpd.Value, variation-point={short-label=vpIN_VePMIR_n_HTAPMaxSpd_Value, sw-syscond=1}
              IN_VePMIR_n_HTAPMinSpd_Value: accessed-variable=VePMIR_n_HTAPMinSpd.Value, variation-point={short-label=vpIN_VePMIR_n_HTAPMinSpd_Value, sw-syscond=1}
              IN_VePMIR_n_HTAP_DVC_RPM_PEClFlwRt_Value: accessed-variable=VePMIR_n_HTAP_DVC_RPM_PEClFlwRt.Value, variation-point={short-label=vpIN_VePMIR_n_HTAP_DVC_RPM_PEClFlwRt_Value, sw-syscond=1}
              IN_VePMIR_n_HTAuxPumpRPMAct_Value: accessed-variable=VePMIR_n_HTAuxPumpRPMAct.Value, variation-point={short-label=vpIN_VePMIR_n_HTAuxPumpRPMAct_Value, sw-syscond=1}
              IN_VePMIR_n_LTAP_DVC_RPM_PEClFlwRt_Value: accessed-variable=VePMIR_n_LTAP_DVC_RPM_PEClFlwRt.Value, variation-point={short-label=vpIN_VePMIR_n_LTAP_DVC_RPM_PEClFlwRt_Value, sw-syscond=1}
              IN_VePMIR_n_LTActvPumpRPMAct_Value: accessed-variable=VePMIR_n_LTActvPumpRPMAct.Value, variation-point={short-label=vpIN_VePMIR_n_LTActvPumpRPMAct_Value, sw-syscond=1}
              IN_VePMIR_n_LTPP2MaxSpd_Value: accessed-variable=VePMIR_n_LTPP2MaxSpd.Value, variation-point={short-label=vpIN_VePMIR_n_LTPP2MaxSpd_Value, sw-syscond=1}
              IN_VePMIR_n_LTPP2MinSpd_Value: accessed-variable=VePMIR_n_LTPP2MinSpd.Value, variation-point={short-label=vpIN_VePMIR_n_LTPP2MinSpd_Value, sw-syscond=1}
              IN_VePMIR_n_LTPP2_DVC_RPM_PEClFlwRt_Value: accessed-variable=VePMIR_n_LTPP2_DVC_RPM_PEClFlwRt.Value, variation-point={short-label=vpIN_VePMIR_n_LTPP2_DVC_RPM_PEClFlwRt_Value, sw-syscond=1}
              IN_VePMIR_n_LTPPMaxSpd_Value: accessed-variable=VePMIR_n_LTPPMaxSpd.Value, variation-point={short-label=vpIN_VePMIR_n_LTPPMaxSpd_Value, sw-syscond=1}
              IN_VePMIR_n_LTPPMinSpd_Value: accessed-variable=VePMIR_n_LTPPMinSpd.Value, variation-point={short-label=vpIN_VePMIR_n_LTPPMinSpd_Value, sw-syscond=1}
              IN_VePMIR_n_LTPP_DVC_RPM_PEClFlwRt_Value: accessed-variable=VePMIR_n_LTPP_DVC_RPM_PEClFlwRt.Value, variation-point={short-label=vpIN_VePMIR_n_LTPP_DVC_RPM_PEClFlwRt_Value, sw-syscond=1}
              IN_VePMIR_n_LTPsvPump2ActSpd_Value: accessed-variable=VePMIR_n_LTPsvPump2ActSpd.Value, variation-point={short-label=vpIN_VePMIR_n_LTPsvPump2ActSpd_Value, sw-syscond=1}
              IN_VePMIR_n_LTPsvPump2RPMAct_Value: accessed-variable=VePMIR_n_LTPsvPump2RPMAct.Value, variation-point={short-label=vpIN_VePMIR_n_LTPsvPump2RPMAct_Value, sw-syscond=1}
              IN_VePMIR_n_LTPsvPumpActSpd_Value: accessed-variable=VePMIR_n_LTPsvPumpActSpd.Value, variation-point={short-label=vpIN_VePMIR_n_LTPsvPumpActSpd_Value, sw-syscond=1}
              IN_VePMIR_n_LTPsvPump_RPMAct_Value: accessed-variable=VePMIR_n_LTPsvPump_RPMAct.Value, variation-point={short-label=vpIN_VePMIR_n_LTPsvPump_RPMAct_Value, sw-syscond=1}
              IN_VePMTR_e_ThrmlDevEnbl_Value: accessed-variable=VePMTR_e_ThrmlDevEnbl.Value, variation-point={short-label=vpIN_VePMTR_e_ThrmlDevEnbl_Value, sw-syscond=1}
              IN_VeRCVR_b_HT_Shtoff_VlvCmd_Value: accessed-variable=VeRCVR_b_HT_Shtoff_VlvCmd.Value, variation-point={short-label=vpIN_VeRCVR_b_HT_Shtoff_VlvCmd_Value, sw-syscond=1}
              IN_VeRCVR_e_CPV_Valve_Stuck_State_Value: accessed-variable=VeRCVR_e_CPV_Valve_Stuck_State.Value, variation-point={short-label=vpIN_VeRCVR_e_CPV_Valve_Stuck_State_Value, sw-syscond=1}
              IN_VeRCVR_e_HTL_Valve_Stuck_State_Value: accessed-variable=VeRCVR_e_HTL_Valve_Stuck_State.Value, variation-point={short-label=vpIN_VeRCVR_e_HTL_Valve_Stuck_State_Value, sw-syscond=1}
              IN_VeRCVR_e_LTR_Valve_Stuck_State_Value: accessed-variable=VeRCVR_e_LTR_Valve_Stuck_State.Value, variation-point={short-label=vpIN_VeRCVR_e_LTR_Valve_Stuck_State_Value, sw-syscond=1}
              IN_VeTAIR_Pct_FrWyVlv_PstnAct_Value: accessed-variable=VeTAIR_Pct_FrWyVlv_PstnAct.Value, variation-point={short-label=vpIN_VeTAIR_Pct_FrWyVlv_PstnAct_Value, sw-syscond=1}
              IN_VeTAIR_Pct_HTL_BypsVlv_ActlPstn_Value: accessed-variable=VeTAIR_Pct_HTL_BypsVlv_ActlPstn.Value, variation-point={short-label=vpIN_VeTAIR_Pct_HTL_BypsVlv_ActlPstn_Value, sw-syscond=1}
              IN_VeTAIR_Pct_LTR_BypsVlv_ActlPstn_Value: accessed-variable=VeTAIR_Pct_LTR_BypsVlv_ActlPstn.Value, variation-point={short-label=vpIN_VeTAIR_Pct_LTR_BypsVlv_ActlPstn_Value, sw-syscond=1}
              IN_VeTAIR_b_FrWyVlv_PstnAct_FA_Value: accessed-variable=VeTAIR_b_FrWyVlv_PstnAct_FA.Value, variation-point={short-label=vpIN_VeTAIR_b_FrWyVlv_PstnAct_FA_Value, sw-syscond=1}
              IN_VeTAIR_b_HTL_BypsVlv_ActlPstn_FA_Value: accessed-variable=VeTAIR_b_HTL_BypsVlv_ActlPstn_FA.Value, variation-point={short-label=vpIN_VeTAIR_b_HTL_BypsVlv_ActlPstn_FA_Value, sw-syscond=1}
              IN_VeTAIR_b_LTR_BypsVlv_ActlPstn_FA_Value: accessed-variable=VeTAIR_b_LTR_BypsVlv_ActlPstn_FA.Value, variation-point={short-label=vpIN_VeTAIR_b_LTR_BypsVlv_ActlPstn_FA_Value, sw-syscond=1}
              IN_VeTHMR_Pct_FCCP_Req_Value: accessed-variable=VeTHMR_Pct_FCCP_Req.Value, variation-point={short-label=vpIN_VeTHMR_Pct_FCCP_Req_Value, sw-syscond=1}
              IN_VeTHMR_T_AHPInletTempArb_Value: accessed-variable=VeTHMR_T_AHPInletTempArb.Value, variation-point={short-label=vpIN_VeTHMR_T_AHPInletTempArb_Value, sw-syscond=1}
              IN_VeTHMR_b_HTAuxPmp_ClntWarmUp_Value: accessed-variable=VeTHMR_b_HTAuxPmp_ClntWarmUp.Value, variation-point={short-label=vpIN_VeTHMR_b_HTAuxPmp_ClntWarmUp_Value, sw-syscond=1}
              IN_VeTHMR_b_KeyXstnOFF_Value: accessed-variable=VeTHMR_b_KeyXstnOFF.Value, variation-point={short-label=vpIN_VeTHMR_b_KeyXstnOFF_Value, sw-syscond=1}
              IN_VeTHMR_b_LTActvPmp_ClntWarmUp_Value: accessed-variable=VeTHMR_b_LTActvPmp_ClntWarmUp.Value, variation-point={short-label=vpIN_VeTHMR_b_LTActvPmp_ClntWarmUp_Value, sw-syscond=1}
              IN_VeTHMR_b_LTPsvPmp2_ClntWarmUp_Value: accessed-variable=VeTHMR_b_LTPsvPmp2_ClntWarmUp.Value, variation-point={short-label=vpIN_VeTHMR_b_LTPsvPmp2_ClntWarmUp_Value, sw-syscond=1}
              IN_VeTHMR_b_LTPsvPmp_ClntWarmUp_Value: accessed-variable=VeTHMR_b_LTPsvPmp_ClntWarmUp.Value, variation-point={short-label=vpIN_VeTHMR_b_LTPsvPmp_ClntWarmUp_Value, sw-syscond=1}
              IN_VeTHMR_b_VhclStatus_Value: accessed-variable=VeTHMR_b_VhclStatus.Value, variation-point={short-label=vpIN_VeTHMR_b_VhclStatus_Value, sw-syscond=1}
              IN_VeTHMR_dV_Branch_{1..3}_Flw_Value: accessed-variable=VeTHMR_dV_Branch_{1..3}_Flw.Value, variation-point={short-label=vpIN_VeTHMR_dV_Branch_{1..3}_Flw_Value, sw-syscond=1}
              IN_VeTHMR_dV_HT_AuxPmpFlow_Value: accessed-variable=VeTHMR_dV_HT_AuxPmpFlow.Value, variation-point={short-label=vpIN_VeTHMR_dV_HT_AuxPmpFlow_Value, sw-syscond=1}
              IN_VeTHMR_dV_LTR_Flw_Tgt_Value: accessed-variable=VeTHMR_dV_LTR_Flw_Tgt.Value, variation-point={short-label=vpIN_VeTHMR_dV_LTR_Flw_Tgt_Value, sw-syscond=1}
              IN_VeTHMR_dV_LT_ActvPmpFlow_Value: accessed-variable=VeTHMR_dV_LT_ActvPmpFlow.Value, variation-point={short-label=vpIN_VeTHMR_dV_LT_ActvPmpFlow_Value, sw-syscond=1}
              IN_VeTHMR_dV_LT_PsvPmp2Flow_Value: accessed-variable=VeTHMR_dV_LT_PsvPmp2Flow.Value, variation-point={short-label=vpIN_VeTHMR_dV_LT_PsvPmp2Flow_Value, sw-syscond=1}
              IN_VeTHMR_dV_LT_PsvPmpFlow_Value: accessed-variable=VeTHMR_dV_LT_PsvPmpFlow.Value, variation-point={short-label=vpIN_VeTHMR_dV_LT_PsvPmpFlow_Value, sw-syscond=1}
              IN_VeTHMR_e_BatThrmlSt_Value: accessed-variable=VeTHMR_e_BatThrmlSt.Value, variation-point={short-label=vpIN_VeTHMR_e_BatThrmlSt_Value, sw-syscond=1}
              IN_VeTHMR_e_ClntPmpState_Value: accessed-variable=VeTHMR_e_ClntPmpState.Value, variation-point={short-label=vpIN_VeTHMR_e_ClntPmpState_Value, sw-syscond=1}
              IN_VeTHMR_e_HCP_LTP_FanAftRun_Rq_Value: accessed-variable=VeTHMR_e_HCP_LTP_FanAftRun_Rq.Value, variation-point={short-label=vpIN_VeTHMR_e_HCP_LTP_FanAftRun_Rq_Value, sw-syscond=1}
              IN_VeTHMR_n_BTLPumpMBCReq_Value: accessed-variable=VeTHMR_n_BTLPumpMBCReq.Value, variation-point={short-label=vpIN_VeTHMR_n_BTLPumpMBCReq_Value, sw-syscond=1}
              IN_VeTHMR_n_HTLPumpMBCReq_Value: accessed-variable=VeTHMR_n_HTLPumpMBCReq.Value, variation-point={short-label=vpIN_VeTHMR_n_HTLPumpMBCReq_Value, sw-syscond=1}
              IN_VeTHMR_n_LTLPECP1MBC_Value: accessed-variable=VeTHMR_n_LTLPECP1MBC.Value, variation-point={short-label=vpIN_VeTHMR_n_LTLPECP1MBC_Value, sw-syscond=1}
              IN_VeTHMR_n_LTLPECP2MBC_Value: accessed-variable=VeTHMR_n_LTLPECP2MBC.Value, variation-point={short-label=vpIN_VeTHMR_n_LTLPECP2MBC_Value, sw-syscond=1}
              IN_VeTHMR_y_ClntPump_Oprtng_State_Value: accessed-variable=VeTHMR_y_ClntPump_Oprtng_State.Value, variation-point={short-label=vpIN_VeTHMR_y_ClntPump_Oprtng_State_Value, sw-syscond=1}
              IN_VeTHMR_y_ClntPump_Slctd_State_Value: accessed-variable=VeTHMR_y_ClntPump_Slctd_State.Value, variation-point={short-label=vpIN_VeTHMR_y_ClntPump_Slctd_State_Value, sw-syscond=1}
              IN_VeTHMR_y_PumpEnbl_Value: accessed-variable=VeTHMR_y_PumpEnbl.Value, variation-point={short-label=vpIN_VeTHMR_y_PumpEnbl_Value, sw-syscond=1}
              IN_VeTMIR_T_ElecClntHtr_TmpIn_Value: accessed-variable=VeTMIR_T_ElecClntHtr_TmpIn.Value, variation-point={short-label=vpIN_VeTMIR_T_ElecClntHtr_TmpIn_Value, sw-syscond=1}
              IN_VeTMIR_T_LTR_ClntTmpOut_Value: accessed-variable=VeTMIR_T_LTR_ClntTmpOut.Value, variation-point={short-label=vpIN_VeTMIR_T_LTR_ClntTmpOut_Value, sw-syscond=1}
              IN_VeTMIR_T_OnBrdChrg_ClntTmpIn_Value: accessed-variable=VeTMIR_T_OnBrdChrg_ClntTmpIn.Value, variation-point={short-label=vpIN_VeTMIR_T_OnBrdChrg_ClntTmpIn_Value, sw-syscond=1}
              IN_VeTMIR_T_PsvPmpClnt_TmpIn_Value: accessed-variable=VeTMIR_T_PsvPmpClnt_TmpIn.Value, variation-point={short-label=vpIN_VeTMIR_T_PsvPmpClnt_TmpIn_Value, sw-syscond=1}
              IN_VeTMIR_b_OnBrdChrg_ClntTmpIn_FA_Value: accessed-variable=VeTMIR_b_OnBrdChrg_ClntTmpIn_FA.Value, variation-point={short-label=vpIN_VeTMIR_b_OnBrdChrg_ClntTmpIn_FA_Value, sw-syscond=1}
              IN_VeTMIR_b_PsvPmpClnt_TmpIn_FA_Value: accessed-variable=VeTMIR_b_PsvPmpClnt_TmpIn_FA.Value, variation-point={short-label=vpIN_VeTMIR_b_PsvPmpClnt_TmpIn_FA_Value, sw-syscond=1}
              IN_VeTRIR_T_HV_BatClntTmpOut_Value: accessed-variable=VeTRIR_T_HV_BatClntTmpOut.Value, variation-point={short-label=vpIN_VeTRIR_T_HV_BatClntTmpOut_Value, sw-syscond=1}
              IN_VeTRIR_T_HV_BatClntTmp_In_Value: accessed-variable=VeTRIR_T_HV_BatClntTmp_In.Value, variation-point={short-label=vpIN_VeTRIR_T_HV_BatClntTmp_In_Value, sw-syscond=1}
              IN_VeTRIR_T_HtrCorClnt_TmpIn_Value: accessed-variable=VeTRIR_T_HtrCorClnt_TmpIn.Value, variation-point={short-label=vpIN_VeTRIR_T_HtrCorClnt_TmpIn_Value, sw-syscond=1}
              IN_VeTRIR_T_HtrCorClnt_TmpOut_Value: accessed-variable=VeTRIR_T_HtrCorClnt_TmpOut.Value, variation-point={short-label=vpIN_VeTRIR_T_HtrCorClnt_TmpOut_Value, sw-syscond=1}
          data-send-points:
            65 x access:
              OUT_VePMPR_Pct_LTPsvPumpRPMAct_Value: accessed-variable=VePMPR_Pct_LTPsvPumpRPMAct.Value, variation-point={short-label=vpOUT_VePMPR_Pct_LTPsvPumpRPMAct_Value, sw-syscond=1}
              OUT_VePMPR_e_LT_PsvPmp_FL_SAFE_ACTVT_Value: accessed-variable=VePMPR_e_LT_PsvPmp_FL_SAFE_ACTVT.Value, variation-point={short-label=vpOUT_VePMPR_e_LT_PsvPmp_FL_SAFE_ACTVT_Value, sw-syscond=1}
              OUT_VePMPR_b_LT_PsvPmp_FL_SAFE_ACTVT_FA_Value: accessed-variable=VePMPR_b_LT_PsvPmp_FL_SAFE_ACTVT_FA.Value, variation-point={short-label=vpOUT_VePMPR_b_LT_PsvPmp_FL_SAFE_ACTVT_FA_Value, sw-syscond=1}
              OUT_VePMPR_b_LTPsvPump_Flt_Dtctd_Value: accessed-variable=VePMPR_b_LTPsvPump_Flt_Dtctd.Value, variation-point={short-label=vpOUT_VePMPR_b_LTPsvPump_Flt_Dtctd_Value, sw-syscond=1}
              OUT_VePMPR_b_LT_PsvPmpRely_Sts_Value: accessed-variable=VePMPR_b_LT_PsvPmpRely_Sts.Value, variation-point={short-label=vpOUT_VePMPR_b_LT_PsvPmpRely_Sts_Value, sw-syscond=1}
              OUT_VePMPR_b_LT_PsvPump_PostRunCmd_FA_Value: accessed-variable=VePMPR_b_LT_PsvPump_PostRunCmd_FA.Value, variation-point={short-label=vpOUT_VePMPR_b_LT_PsvPump_PostRunCmd_FA_Value, sw-syscond=1}
              OUT_VePMPR_n_PECP_RPM_Op_St_Value: accessed-variable=VePMPR_n_PECP_RPM_Op_St.Value, variation-point={short-label=vpOUT_VePMPR_n_PECP_RPM_Op_St_Value, sw-syscond=1}
              OUT_VePMPR_e_LTPsvPump_PstRnSt_Value: accessed-variable=VePMPR_e_LTPsvPump_PstRnSt.Value, variation-point={short-label=vpOUT_VePMPR_e_LTPsvPump_PstRnSt_Value, sw-syscond=1}
              OUT_VePMPR_n_LTPP_MaxOpRPM_Value: accessed-variable=VePMPR_n_LTPP_MaxOpRPM.Value, variation-point={short-label=vpOUT_VePMPR_n_LTPP_MaxOpRPM_Value, sw-syscond=1}
              OUT_VePMPR_e_LT_PsvPmp2_FL_SAFE_ACTVT_Value: accessed-variable=VePMPR_e_LT_PsvPmp2_FL_SAFE_ACTVT.Value, variation-point={short-label=vpOUT_VePMPR_e_LT_PsvPmp2_FL_SAFE_ACTVT_Value, sw-syscond=1}
              OUT_VePMPR_b_LT_PsvPmp2_FL_SAFE_ACTVT_FA_Value: accessed-variable=VePMPR_b_LT_PsvPmp2_FL_SAFE_ACTVT_FA.Value, variation-point={short-label=vpOUT_VePMPR_b_LT_PsvPmp2_FL_SAFE_ACTVT_FA_Value, sw-syscond=1}
              OUT_VePMPR_e_LTPsvPump2_PstRnSt_Value: accessed-variable=VePMPR_e_LTPsvPump2_PstRnSt.Value, variation-point={short-label=vpOUT_VePMPR_e_LTPsvPump2_PstRnSt_Value, sw-syscond=1}
              OUT_VePMPR_b_LT_PsvPump2_PostRunCmd_FA_Value: accessed-variable=VePMPR_b_LT_PsvPump2_PostRunCmd_FA.Value, variation-point={short-label=vpOUT_VePMPR_b_LT_PsvPump2_PostRunCmd_FA_Value, sw-syscond=1}
              OUT_VePMPR_b_LTPsvPump2_Flt_Dtctd_Value: accessed-variable=VePMPR_b_LTPsvPump2_Flt_Dtctd.Value, variation-point={short-label=vpOUT_VePMPR_b_LTPsvPump2_Flt_Dtctd_Value, sw-syscond=1}
              OUT_VePMPR_n_PECP2_RPM_Op_St_Value: accessed-variable=VePMPR_n_PECP2_RPM_Op_St.Value, variation-point={short-label=vpOUT_VePMPR_n_PECP2_RPM_Op_St_Value, sw-syscond=1}
              OUT_VePMPR_n_LTPP2_MaxOpRPM_Value: accessed-variable=VePMPR_n_LTPP2_MaxOpRPM.Value, variation-point={short-label=vpOUT_VePMPR_n_LTPP2_MaxOpRPM_Value, sw-syscond=1}
              OUT_VePMPR_Pct_LTPsvPump2RPMAct_Value: accessed-variable=VePMPR_Pct_LTPsvPump2RPMAct.Value, variation-point={short-label=vpOUT_VePMPR_Pct_LTPsvPump2RPMAct_Value, sw-syscond=1}
              OUT_VePMPR_n_LT_ActvPmpCmd_Value: accessed-variable=VePMPR_n_LT_ActvPmpCmd.Value, variation-point={short-label=vpOUT_VePMPR_n_LT_ActvPmpCmd_Value, sw-syscond=1}
              OUT_VePMPR_e_LT_ActvPmp_PostRunCmd_Value: accessed-variable=VePMPR_e_LT_ActvPmp_PostRunCmd.Value, variation-point={short-label=vpOUT_VePMPR_e_LT_ActvPmp_PostRunCmd_Value, sw-syscond=1}
              OUT_VePMPR_b_LT_ActvPump_PostRunCmd_FA_Value: accessed-variable=VePMPR_b_LT_ActvPump_PostRunCmd_FA.Value, variation-point={short-label=vpOUT_VePMPR_b_LT_ActvPump_PostRunCmd_FA_Value, sw-syscond=1}
              OUT_VePMPR_e_LT_ActPumpFS_Actv_Value: accessed-variable=VePMPR_e_LT_ActPumpFS_Actv.Value, variation-point={short-label=vpOUT_VePMPR_e_LT_ActPumpFS_Actv_Value, sw-syscond=1}
              OUT_VePMPR_b_LT_ActvPmpRely_Sts_Value: accessed-variable=VePMPR_b_LT_ActvPmpRely_Sts.Value, variation-point={short-label=vpOUT_VePMPR_b_LT_ActvPmpRely_Sts_Value, sw-syscond=1}
              OUT_VePMPR_Pct_LT_ActPmp_Cmd_Value: accessed-variable=VePMPR_Pct_LT_ActPmp_Cmd.Value, variation-point={short-label=vpOUT_VePMPR_Pct_LT_ActPmp_Cmd_Value, sw-syscond=1}
              OUT_VePMPR_b_LTActPump_Flt_Dtctd_Value: accessed-variable=VePMPR_b_LTActPump_Flt_Dtctd.Value, variation-point={short-label=vpOUT_VePMPR_b_LTActPump_Flt_Dtctd_Value, sw-syscond=1}
              OUT_VePMPR_e_LTActPmp_FL_SAFE_ACTVT_Value: accessed-variable=VePMPR_e_LTActPmp_FL_SAFE_ACTVT.Value, variation-point={short-label=vpOUT_VePMPR_e_LTActPmp_FL_SAFE_ACTVT_Value, sw-syscond=1}
              OUT_VePMPR_b_LT_ActPmp_FL_SAFE_ACTVT_FA_Value: accessed-variable=VePMPR_b_LT_ActPmp_FL_SAFE_ACTVT_FA.Value, variation-point={short-label=vpOUT_VePMPR_b_LT_ActPmp_FL_SAFE_ACTVT_FA_Value, sw-syscond=1}
              OUT_VePMPR_dV_BattFlw_Value: accessed-variable=VePMPR_dV_BattFlw.Value, variation-point={short-label=vpOUT_VePMPR_dV_BattFlw_Value, sw-syscond=1}
              OUT_VePMPR_b_RdyToShtDwn_Value: accessed-variable=VePMPR_b_RdyToShtDwn.Value, variation-point={short-label=vpOUT_VePMPR_b_RdyToShtDwn_Value, sw-syscond=1}
              OUT_VePMPR_n_LTAP_MaxOpRPM_Value: accessed-variable=VePMPR_n_LTAP_MaxOpRPM.Value, variation-point={short-label=vpOUT_VePMPR_n_LTAP_MaxOpRPM_Value, sw-syscond=1}
              OUT_VePMPR_b_HT_AuxPump_PostRunCmd_FA_Value: accessed-variable=VePMPR_b_HT_AuxPump_PostRunCmd_FA.Value, variation-point={short-label=vpOUT_VePMPR_b_HT_AuxPump_PostRunCmd_FA_Value, sw-syscond=1}
              OUT_VePMPR_n_HTAuxPumpRPMAct_Value: accessed-variable=VePMPR_n_HTAuxPumpRPMAct.Value, variation-point={short-label=vpOUT_VePMPR_n_HTAuxPumpRPMAct_Value, sw-syscond=1}
              OUT_VePMPR_e_HT_AuxPmp_FL_SAFE_ACTVT_Value: accessed-variable=VePMPR_e_HT_AuxPmp_FL_SAFE_ACTVT.Value, variation-point={short-label=vpOUT_VePMPR_e_HT_AuxPmp_FL_SAFE_ACTVT_Value, sw-syscond=1}
              OUT_VePMPR_b_HT_AuxPmp_FL_SAFE_ACTVT_FA_Value: accessed-variable=VePMPR_b_HT_AuxPmp_FL_SAFE_ACTVT_FA.Value, variation-point={short-label=vpOUT_VePMPR_b_HT_AuxPmp_FL_SAFE_ACTVT_FA_Value, sw-syscond=1}
              OUT_VePMPR_b_HT_AuxPmpRely_Sts_Value: accessed-variable=VePMPR_b_HT_AuxPmpRely_Sts.Value, variation-point={short-label=vpOUT_VePMPR_b_HT_AuxPmpRely_Sts_Value, sw-syscond=1}
              OUT_VePMPR_n_HT_AuxPmpCmd_Value: accessed-variable=VePMPR_n_HT_AuxPmpCmd.Value, variation-point={short-label=vpOUT_VePMPR_n_HT_AuxPmpCmd_Value, sw-syscond=1}
              OUT_VePMPR_Pct_HT_AuxPmpCmd_Value: accessed-variable=VePMPR_Pct_HT_AuxPmpCmd.Value, variation-point={short-label=vpOUT_VePMPR_Pct_HT_AuxPmpCmd_Value, sw-syscond=1}
              OUT_VePMPR_e_HT_AuxPmp_PostRunCmd_Value: accessed-variable=VePMPR_e_HT_AuxPmp_PostRunCmd.Value, variation-point={short-label=vpOUT_VePMPR_e_HT_AuxPmp_PostRunCmd_Value, sw-syscond=1}
              OUT_VePMPR_n_HTAP_MaxOpRPM_Value: accessed-variable=VePMPR_n_HTAP_MaxOpRPM.Value, variation-point={short-label=vpOUT_VePMPR_n_HTAP_MaxOpRPM_Value, sw-syscond=1}
              OUT_VePMPR_dV_HtrFlw_Value: accessed-variable=VePMPR_dV_HtrFlw.Value, variation-point={short-label=vpOUT_VePMPR_dV_HtrFlw_Value, sw-syscond=1}
              OUT_VePMPR_n_FCCP_CtrlSpd_Value: accessed-variable=VePMPR_n_FCCP_CtrlSpd.Value, variation-point={short-label=vpOUT_VePMPR_n_FCCP_CtrlSpd_Value, sw-syscond=1}
              OUT_VePMPR_b_HTAuxPump_Flt_Dtctd_Value: accessed-variable=VePMPR_b_HTAuxPump_Flt_Dtctd.Value, variation-point={short-label=vpOUT_VePMPR_b_HTAuxPump_Flt_Dtctd_Value, sw-syscond=1}
              OUT_VePMPR_n_FCCP_SetCtrlSpd_Value: accessed-variable=VePMPR_n_FCCP_SetCtrlSpd.Value, variation-point={short-label=vpOUT_VePMPR_n_FCCP_SetCtrlSpd_Value, sw-syscond=1}
              OUT_VePMPR_e_FCCP_Default_VltgRngSlct_Value: accessed-variable=VePMPR_e_FCCP_Default_VltgRngSlct.Value, variation-point={short-label=vpOUT_VePMPR_e_FCCP_Default_VltgRngSlct_Value, sw-syscond=1}
              OUT_VePMPR_U_FCCP_Vltg_Enter_Default_Run_Value: accessed-variable=VePMPR_U_FCCP_Vltg_Enter_Default_Run.Value, variation-point={short-label=vpOUT_VePMPR_U_FCCP_Vltg_Enter_Default_Run_Value, sw-syscond=1}
              OUT_VePMPR_U_FCCP_VltgExitDefaultRun_Value: accessed-variable=VePMPR_U_FCCP_VltgExitDefaultRun.Value, variation-point={short-label=vpOUT_VePMPR_U_FCCP_VltgExitDefaultRun_Value, sw-syscond=1}
              OUT_VePMPR_t_FCCP_TimeExitDefaultRun_Value: accessed-variable=VePMPR_t_FCCP_TimeExitDefaultRun.Value, variation-point={short-label=vpOUT_VePMPR_t_FCCP_TimeExitDefaultRun_Value, sw-syscond=1}
              OUT_VePMPR_b_FCCP_Enbl_Value: accessed-variable=VePMPR_b_FCCP_Enbl.Value, variation-point={short-label=vpOUT_VePMPR_b_FCCP_Enbl_Value, sw-syscond=1}
              OUT_VePMPR_e_LT_PsvPmp_PostRunCmd_Value: accessed-variable=VePMPR_e_LT_PsvPmp_PostRunCmd.Value, variation-point={short-label=vpOUT_VePMPR_e_LT_PsvPmp_PostRunCmd_Value, sw-syscond=1}
              OUT_VePMPR_n_LT_PsvPmpCmd_Value: accessed-variable=VePMPR_n_LT_PsvPmpCmd.Value, variation-point={short-label=vpOUT_VePMPR_n_LT_PsvPmpCmd_Value, sw-syscond=1}
              OUT_VePMPR_Pct_LT_PsvPmpCmd_Value: accessed-variable=VePMPR_Pct_LT_PsvPmpCmd.Value, variation-point={short-label=vpOUT_VePMPR_Pct_LT_PsvPmpCmd_Value, sw-syscond=1}
              OUT_VePMPR_e_LT_PsvPmp2_PostRunCmd_Value: accessed-variable=VePMPR_e_LT_PsvPmp2_PostRunCmd.Value, variation-point={short-label=vpOUT_VePMPR_e_LT_PsvPmp2_PostRunCmd_Value, sw-syscond=1}
              OUT_VePMPR_n_LT_PsvPmp2Cmd_Value: accessed-variable=VePMPR_n_LT_PsvPmp2Cmd.Value, variation-point={short-label=vpOUT_VePMPR_n_LT_PsvPmp2Cmd_Value, sw-syscond=1}
              OUT_VePMPR_Pct_LT_PsvPmp2Cmd_Value: accessed-variable=VePMPR_Pct_LT_PsvPmp2Cmd.Value, variation-point={short-label=vpOUT_VePMPR_Pct_LT_PsvPmp2Cmd_Value, sw-syscond=1}
              OUT_VePMPR_dV_LTRFlw_Value: accessed-variable=VePMPR_dV_LTRFlw.Value
              OUT_VePMPR_dV_DualPump_PEBrnchFlw_Value: accessed-variable=VePMPR_dV_DualPump_PEBrnchFlw.Value
              OUT_VePMPR_b_DualPump_PEBrnchFlw_FA_Value: accessed-variable=VePMPR_b_DualPump_PEBrnchFlw_FA.Value
              OUT_VePMPR_dV_PwrElecsFlw_Value: accessed-variable=VePMPR_dV_PwrElecsFlw.Value
              OUT_VePMPR_dV_MtrFlw_Value: accessed-variable=VePMPR_dV_MtrFlw.Value
              OUT_VePMPR_dV_GenFlw_Value: accessed-variable=VePMPR_dV_GenFlw.Value
              OUT_VePMPR_dV_FuelCellFlw_Value: accessed-variable=VePMPR_dV_FuelCellFlw.Value, variation-point={short-label=vpOUT_VePMPR_dV_FuelCellFlw_Value, sw-syscond=1}
              OUT_VePMPR_dV_FEDMFlw_Value: accessed-variable=VePMPR_dV_FEDMFlw.Value
              OUT_VePMPR_dV_REDMFlw_Value: accessed-variable=VePMPR_dV_REDMFlw.Value
              OUT_VePMPR_b_FEDMFlw_FA_Value: accessed-variable=VePMPR_b_FEDMFlw_FA.Value, variation-point={short-label=vpOUT_VePMPR_b_FEDMFlw_FA_Value, sw-syscond=1}
              OUT_VePMPR_b_REDMFlw_FA_Value: accessed-variable=VePMPR_b_REDMFlw_FA.Value, variation-point={short-label=vpOUT_VePMPR_b_REDMFlw_FA_Value, sw-syscond=1}
              OUT_VePMPR_b_GenFlw_FA_Value: accessed-variable=VePMPR_b_GenFlw_FA.Value, variation-point={short-label=vpOUT_VePMPR_b_GenFlw_FA_Value, sw-syscond=1}
        PMPR_PwrOff
          data-send-points:
            6 x access:
              OUT_NePMPR_n_LT_PsvPmpCmd_AD_NePMPR_n_LT_PsvPmpCmd_AD: accessed-variable=NePMPR_n_LT_PsvPmpCmd_AD.NePMPR_n_LT_PsvPmpCmd_AD
              OUT_NePMPR_e_LT_PsvPmp_PostRunCmd_AD_NePMPR_e_LT_PsvPmp_PostRunCmd_AD: accessed-variable=NePMPR_e_LT_PsvPmp_PostRunCmd_AD.NePMPR_e_LT_PsvPmp_PostRunCmd_AD
              OUT_NePMPR_n_LT_PsvPmp2Cmd_AD_NePMPR_n_LT_PsvPmp2Cmd_AD: accessed-variable=NePMPR_n_LT_PsvPmp2Cmd_AD.NePMPR_n_LT_PsvPmp2Cmd_AD
              OUT_NePMPR_e_LT_PsvPmp2_PostRunCmd_AD_NePMPR_e_LT_PsvPmp2_PostRunCmd_AD: accessed-variable=NePMPR_e_LT_PsvPmp2_PostRunCmd_AD.NePMPR_e_LT_PsvPmp2_PostRunCmd_AD
              OUT_NePMPR_e_LTPsvPump_PstRnSt_NePMPR_e_LTPsvPump_PstRnSt: accessed-variable=NePMPR_e_LTPsvPump_PstRnSt.NePMPR_e_LTPsvPump_PstRnSt
              OUT_NePMPR_e_LTPsvPump2_PstRnSt_NePMPR_e_LTPsvPump2_PstRnSt: accessed-variable=NePMPR_e_LTPsvPump2_PstRnSt.NePMPR_e_LTPsvPump2_PstRnSt
      20 x variation point proxy, all with category=CONDITION:
        Variant_PMPR_FUNC_1: condition-access=0
        Variant_PMPR_FUNC_10: condition-access=0
        Variant_PMPR_FUNC_{15..17}: condition-access=1
        Variant_PMPR_FUNC_18: condition-access=0
        Variant_PMPR_FUNC_{19..26}: condition-access=1
        Variant_PMPR_FUNC_{3..5}: condition-access=0
        Variant_PMPR_FUNC_6: condition-access=1
        Variant_PMPR_FUNC_7: condition-access=1
        Variant_PMPR_FUNC_9: condition-access=1
